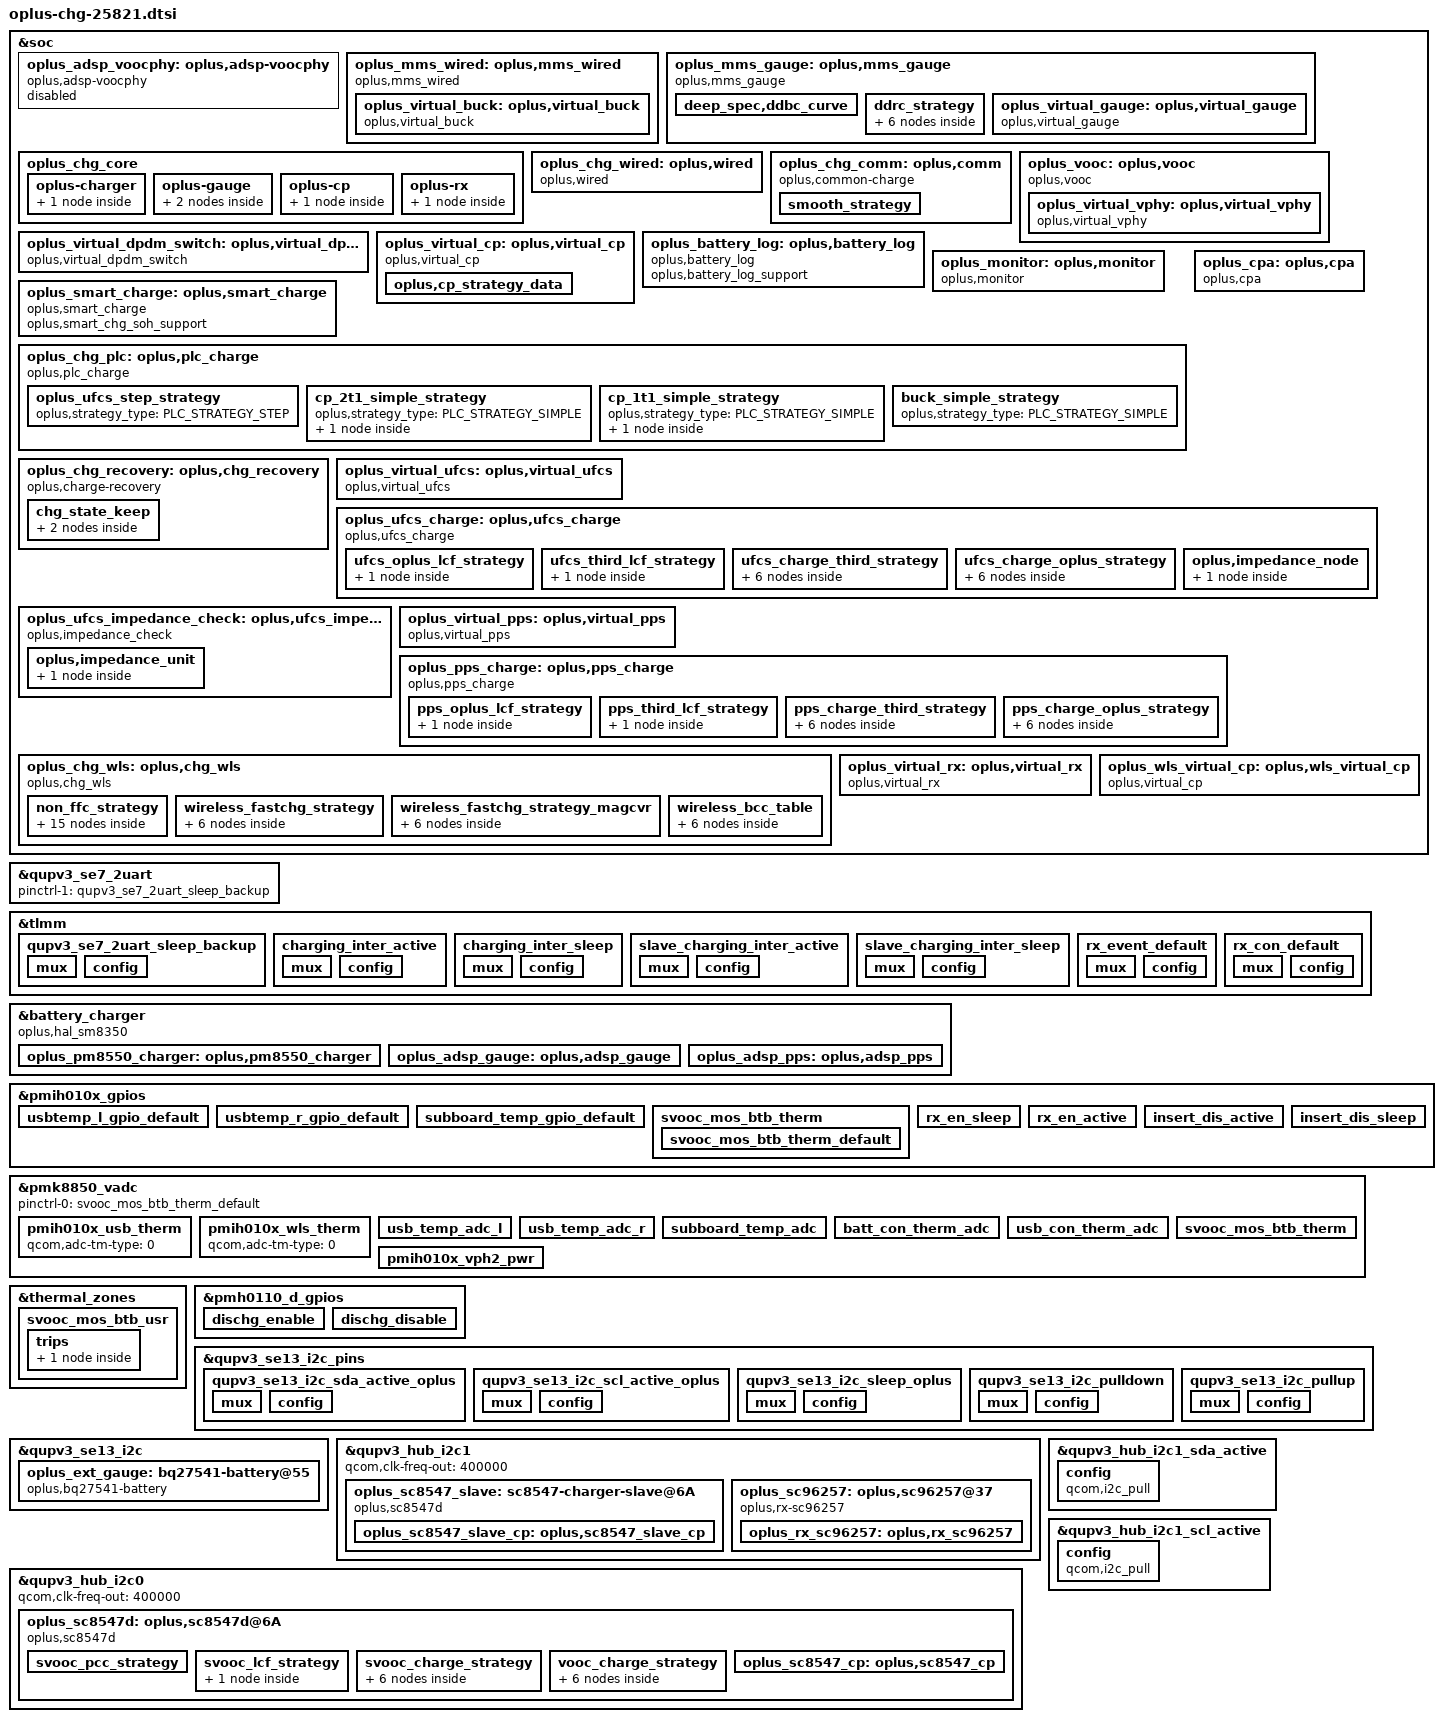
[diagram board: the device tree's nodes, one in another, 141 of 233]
#include "oplus-chg-8850.h.dtsi"
#include "oplus-chg-25821-fw.dtsi"

&soc {
	oplus_adsp_voocphy: oplus,adsp-voocphy {
		status = "disabled";
		compatible = "oplus,adsp-voocphy";
	};

	oplus_mms_wired: oplus,mms_wired {
		compatible = "oplus,mms_wired";
		oplus,buck_ic = <&oplus_virtual_buck>;
		oplus,voocphy_ic = <&oplus_virtual_vphy>;
		oplus,adc_info_name = "855";
		high-temp-scheme;

		oplus,support_usbtemp_protect_v2;
		oplus_spec,usbtemp_batt_temp_low = <50>;
		oplus_spec,usbtemp_batt_temp_high = <50>;
		oplus_spec,usbtemp_batt_temp_over_hot = <60>;
		oplus_spec,usbtemp_ntc_temp_low = <57>;
		oplus_spec,usbtemp_ntc_temp_high = <69>;
		oplus_spec,usbtemp_temp_gap_low_with_batt_temp = <7>;
		oplus_spec,usbtemp_temp_gap_with_batt_temp_in_over_hot = <15>;
		oplus_spec,usbtemp_temp_gap_high_with_batt_temp = <12>;
		oplus_spec,usbtemp_temp_gap_low_without_batt_temp = <12>;
		oplus_spec,usbtemp_temp_gap_high_without_batt_temp = <24>;
		oplus_spec,usbtemp_rise_fast_temp_low = <3>;
		oplus_spec,usbtemp_rise_fast_temp_high = <3>;
		oplus_spec,usbtemp_rise_fast_temp_count_low = <30>;
		oplus_spec,usbtemp_rise_fast_temp_count_high = <20>;
		oplus_spec,usbtemp_cool_down_ntc_low = <54>;
		oplus_spec,usbtemp_cool_down_ntc_high = <65>;
		oplus_spec,usbtemp_cool_down_gap_low = <12>;
		oplus_spec,usbtemp_cool_down_gap_high = <20>;
		oplus_spec,usbtemp_cool_down_recover_ntc_low = <48>;
		oplus_spec,usbtemp_cool_down_recover_ntc_high = <60>;
		oplus_spec,usbtemp_cool_down_recover_gap_low = <6>;
		oplus_spec,usbtemp_cool_down_recover_gap_high = <15>;
		oplus_spec,usbtemp_otg_cc_boot_current_limit = <2000>;

		oplus_virtual_buck: oplus,virtual_buck {
			compatible = "oplus,virtual_buck";
			oplus,buck_ic = <&oplus_pm8550_charger>;
			oplus,buck_ic_index = <0>;
			oplus,buck_ic_connect = <OPLUS_CHG_IC_CONNECT_PARALLEL>;
			oplus,main_charger = <0>;
			oplus,buck_ic_current_ratio = <100>;
			oplus,buck_ic_func_group = <&plat_pm8550_groups>;

			oplus,ic_type = <OPLUS_CHG_IC_VIRTUAL_BUCK>;
			oplus,ic_index = <0>;

			oplus,dischg-gpio = <&pmh0110_d_gpios 5 0x00>;
			oplus,usbtemp_conversion_ratio = <10>;

			pinctrl-names = "usbtemp_l_gpio_default", "usbtemp_r_gpio_default",
						"dischg_enable", "dischg_disable";
			pinctrl-0 = <&usbtemp_l_gpio_default>;
			pinctrl-1 = <&usbtemp_r_gpio_default>;
			pinctrl-2 = <&dischg_enable>;
			pinctrl-3 = <&dischg_disable>;

			io-channels = <&pmk8850_vadc PMIH010X_ADC5_GEN4_AMUX1_GPIO6_100K_PU(1, PMIH010X_SID)>,
					      <&pmk8850_vadc PMIH010X_ADC5_GEN4_AMUX5_GPIO18_100K_PU(1, PMIH010X_SID)>;
			io-channel-names = "usb_temp_adc_l", "usb_temp_adc_r";

			oplus,uart_tx-gpio = <&tlmm 62 0x00>;
			oplus,uart_rx-gpio = <&tlmm 63 0x00>;
		};
	};

	oplus_mms_gauge: oplus,mms_gauge {
		compatible = "oplus,mms_gauge";
		oplus,gauge_ic = <&oplus_virtual_gauge>;
		oplus,topic-update-interval = <5000>;
		oplus,support_subboard_ntc;
		oplus,sub_btb_curr_limit = <3000>;
		oplus,fcl_support;
		oplus,fcl_index = <0>;
		oplus,vb_offset = <20>;

		deep_spec,support;
		deep_spec,uv_thr = <2750>;
		deep_spec,count_thr = <50>;
		deep_spec,vbat_soc = <80>;
		deep_spec,count_step = <0 10 0
					350 12 1
					450 15 2
					530 20 3>;

		deep_spec,term_coeff = <2900 600 2
					2910 600 2
					2950 650 3
					3000 650 4
					3010 650 4
					3050 750 6
					3100 800 8
					3110 800 8
					3150 900 10
					3160 900 10
					3200 1000 12
					3210 1000 12
					3260 1050 12>;
		deep_spec,ddrc_strategy_name = "ddrc_curve_v2";
		deep_spec,volt_step = <20>;
		deep_spec,ddbc_curve {
			oplus,temp_type = <OPLUS_STRATEGY_USE_BATT_TEMP>;
			oplus,temp_range = <(-100) 0 200>;
			deep_spec,ddbc_temp_cold = <500 3250 5
						   10000 3200 2>;
			deep_spec,ddbc_temp_cool = <500 3250 5
						   10000 3200 2>;
			deep_spec,ddbc_temp_normal = <500 3250 5
						   10000 3200 2>;
			deep_spec,ddbc_temp_warm = <500 3250 5
						   10000 3200 2>;
		};

		ddrc_strategy {
			oplus,temp_type = <OPLUS_STRATEGY_USE_BATT_TEMP>;
			oplus,ratio_range = <20 30 50 70 90>;
			oplus,temp_range = <(-100) 0 100 200 350>;
			strategy_ratio_range_min {
				strategy_temp_0 =	<0 2753 3000 0
							300 2910 3100 1
							700 3010 3150 2
							1100 3061 3160 3
							1500 3111 3210 4
							1900 3161 3260 5>;
				strategy_temp_1 =	<0 2752 3100 0
							400 2910 3100 1
							900 3010 3150 2
							1400 3061 3160 3
							1900 3111 3210 4
							2400 3161 3260 5>;
				strategy_temp_2 =	<0 2752 3100 0
							400 2910 3100 1
							900 3010 3150 2
							1400 3061 3160 3
							1900 3111 3210 4
							2400 3161 3260 5>;
				strategy_temp_3 =	<0 2751 2950 0
							400 2911 3000 1
							900 3000 3010 2
							1400 3060 3110 3
							1900 3110 3160 4
							2400 3160 3210 5>;
				strategy_temp_4 =	<0 2750 2900 0
							400 2900 2910 1
							900 3000 3010 2
							1400 3050 3050 3
							1900 3100 3100 4
							2400 3150 3150 5>;
				strategy_temp_5 =	<0 2750 2900 0
							400 2900 2910 1
							900 3000 3010 2
							1400 3050 3050 3
							1900 3100 3100 4
							2400 3150 3150 5>;
			};
			strategy_ratio_range_low {
				strategy_temp_0 =	<0 2753 3000 0
							250 2910 3100 1
							550 3010 3150 2
							850 3110 3160 3
							1150 3160 3210 4
							1450 3210 3260 5>;
				strategy_temp_1 =	<0 2752 3100 0
							300 2910 3100 1
							700 3010 3150 2
							1100 3061 3160 3
							1500 3111 3210 4
							1900 3161 3260 5>;
				strategy_temp_2 =	<0 2752 3100 0
							300 2910 3100 1
							700 3010 3150 2
							1100 3061 3160 3
							1500 3111 3210 4
							1900 3161 3260 5>;
				strategy_temp_3 =	<0 2751 2950 0
							300 2911 3000 1
							700 3000 3010 2
							1100 3060 3110 3
							1500 3110 3160 4
							1900 3160 3210 5>;
				strategy_temp_4 =	<0 2750 2900 0
							300 2900 2910 1
							700 3000 3010 2
							1100 3050 3050 3
							1500 3100 3100 4
							1900 3150 3150 5>;
				strategy_temp_5 =	<0 2750 2900 0
							300 2900 2910 1
							700 3000 3010 2
							1100 3050 3050 3
							1500 3100 3100 4
							1900 3150 3150 5>;
			};
			strategy_ratio_range_mid_low {
				strategy_temp_0 =	<0 2753 3000 0
							100 2910 3100 1
							250 3010 3150 2
							400 3110 3160 3
							550 3160 3210 4
							700 3210 3260 5>;
				strategy_temp_1 =	<0 2752 3100 0
							100 2910 3100 1
							300 3010 3150 2
							600 3061 3160 3
							900 3111 3210 4
							1200 3161 3260 5>;
				strategy_temp_2 =	<0 2752 3100 0
							100 2910 3100 1
							300 3010 3150 2
							600 3061 3160 3
							900 3111 3210 4
							1200 3161 3260 5>;
				strategy_temp_3 =	<0 2751 2950 0
							100 2911 3000 1
							300 3000 3010 2
							600 3060 3110 3
							900 3110 3160 4
							1200 3160 3210 5>;
				strategy_temp_4 =	<0 2750 2900 0
							100 2900 2910 1
							300 3000 3010 2
							600 3050 3050 3
							900 3100 3100 4
							1200 3150 3150 5>;
				strategy_temp_5 =	<0 2750 2900 0
							100 2900 2910 1
							300 3000 3010 2
							600 3050 3050 3
							900 3100 3100 4
							1200 3150 3150 5>;
			};
			strategy_ratio_range_mid {
				strategy_temp_0 =	<0 2753 3000 0
							50 2910 3100 1
							150 3010 3150 2
							300 3110 3160 3
							450 3160 3210 4
							600 3210 3260 5>;
				strategy_temp_1 =	<0 2752 3100 0
							50 2910 3100 1
							150 3010 3150 2
							350 3061 3160 3
							550 3111 3210 4
							750 3161 3260 5>;
				strategy_temp_2 =	<0 2752 3100 0
							50 2910 3100 1
							150 3010 3150 2
							350 3061 3160 3
							550 3111 3210 4
							750 3161 3260 5>;
				strategy_temp_3 =	<0 2751 2950 0
							50 2911 3000 1
							150 3000 3010 2
							350 3060 3110 3
							550 3110 3160 4
							750 3160 3210 5>;
				strategy_temp_4 =	<0 2750 2900 0
							50 2900 2910 1
							150 3000 3010 2
							350 3050 3050 3
							550 3100 3100 4
							750 3150 3150 5>;
				strategy_temp_5 =	<0 2750 2900 0
							50 2900 2910 1
							150 3000 3010 2
							350 3050 3050 3
							550 3100 3100 4
							750 3150 3150 5>;
			};
			strategy_ratio_range_mid_high {
				strategy_temp_0 =	<0 2753 3000 0
							50 2910 3100 1
							150 3010 3150 2
							250 3110 3160 3
							350 3160 3210 4
							450 3210 3260 5>;
				strategy_temp_1 =	<0 2752 3100 0
							50 2910 3100 1
							150 3010 3150 2
							250 3061 3160 3
							350 3111 3210 4
							450 3161 3260 5>;
				strategy_temp_2 =	<0 2752 3100 0
							50 2910 3100 1
							150 3010 3150 2
							250 3061 3160 3
							350 3111 3210 4
							450 3161 3260 5>;
				strategy_temp_3 =	<0 2751 2950 0
							50 2911 3000 1
							150 3000 3010 2
							250 3060 3110 3
							350 3110 3160 4
							450 3160 3210 5>;
				strategy_temp_4 =	<0 2750 2900 0
							50 2900 2910 1
							150 3000 3010 2
							250 3100 3100 3
							350 3150 3150 4
							450 3200 3200 5>;
				strategy_temp_5 =	<0 2750 2900 0
							50 2900 2910 1
							150 3000 3010 2
							250 3100 3100 3
							350 3150 3150 4
							450 3200 3200 5>;
			};
			strategy_ratio_range_high {
				strategy_temp_0 =	<0 2753 3000 0
							50 2910 3100 1
							150 3010 3150 2
							250 3110 3160 3
							350 3160 3210 4
							450 3210 3260 5>;
				strategy_temp_1 =	<0 2752 3100 0
							50 2910 3100 1
							150 3010 3150 2
							250 3061 3160 3
							350 3111 3210 4
							450 3161 3260 5>;
				strategy_temp_2 =	<0 2752 3100 0
							50 2910 3100 1
							150 3010 3150 2
							250 3061 3160 3
							350 3111 3210 4
							450 3161 3260 5>;
				strategy_temp_3 =	<0 2751 2950 0
							50 2911 3000 1
							150 3000 3010 2
							250 3060 3110 3
							350 3110 3160 4
							450 3160 3210 5>;
				strategy_temp_4 =	<0 2750 2900 0
							50 2900 2910 1
							150 3000 3010 2
							250 3100 3100 3
							350 3150 3150 4
							450 3200 3200 5>;
				strategy_temp_5 =	<0 2750 2900 0
							50 2900 2910 1
							150 3000 3010 2
							250 3100 3100 3
							350 3150 3150 4
							450 3200 3200 5>;
			};
		};
		oplus_virtual_gauge: oplus,virtual_gauge {
			compatible = "oplus,virtual_gauge";
			oplus,gauge_ic = <&oplus_ext_gauge &oplus_adsp_gauge>;
			oplus,gauge_ic_index = <0 1>;
			oplus,gauge_ic_func_group = <&bq27541_groups &oplus_adsp_gauge_groups>;
			oplus,batt_capacity_mah = <7500>;
			oplus,ic_type = <OPLUS_CHG_IC_VIRTUAL_GAUGE>;
			oplus,ic_index = <0>;
		};
	};
};

&soc {
	oplus_chg_core {
		oplus,chg_framework_v2;
		oplus,smart_charging_screenoff;
		oplus,battery_type_by_smem;
		oplus,chg_spec_version = <OPLUS_CHG_SPEC_VER_V3P7>;
		oplus,common-charge-icl-support;

		oplus-charger {
			plat_pm8550_groups: oplus,plat_pm8550-groups {
				functions = <
					OPLUS_IC_FUNC_INIT
					OPLUS_IC_FUNC_EXIT
					OPLUS_IC_FUNC_REG_DUMP
					OPLUS_IC_FUNC_SMT_TEST
					OPLUS_IC_FUNC_BUCK_INPUT_PRESENT
					OPLUS_IC_FUNC_BUCK_INPUT_SUSPEND
					OPLUS_IC_FUNC_BUCK_INPUT_IS_SUSPEND
					OPLUS_IC_FUNC_BUCK_OUTPUT_SUSPEND
					OPLUS_IC_FUNC_BUCK_OUTPUT_IS_SUSPEND
					OPLUS_IC_FUNC_BUCK_GET_CC_ORIENTATION
					OPLUS_IC_FUNC_BUCK_GET_CHARGER_TYPE
					OPLUS_IC_FUNC_BUCK_RERUN_BC12
					OPLUS_IC_FUNC_BUCK_QC_DETECT_ENABLE
					OPLUS_IC_FUNC_BUCK_SHIPMODE_ENABLE
					OPLUS_IC_FUNC_BUCK_SET_QC_CONFIG
					OPLUS_IC_FUNC_BUCK_SET_PD_CONFIG
					OPLUS_IC_FUNC_GET_SHUTDOWN_SOC
					OPLUS_IC_FUNC_BACKUP_SOC
					OPLUS_IC_FUNC_GET_TYPEC_MODE
					OPLUS_IC_FUNC_BUCK_SET_ICL
					OPLUS_IC_FUNC_BUCK_GET_ICL
					OPLUS_IC_FUNC_BUCK_SET_FCC
					OPLUS_IC_FUNC_BUCK_SET_FV
					OPLUS_IC_FUNC_BUCK_SET_ITERM
					OPLUS_IC_FUNC_BUCK_SET_RECHG_VOL
					OPLUS_IC_FUNC_BUCK_GET_INPUT_CURR
					OPLUS_IC_FUNC_BUCK_GET_INPUT_VOL
					OPLUS_IC_FUNC_BUCK_AICL_RERUN
					OPLUS_IC_FUNC_BUCK_ITEM_CHECK
					OPLUS_IC_FUNC_GET_CHARGER_CYCLE
					OPLUS_IC_FUNC_OTG_BOOST_ENABLE
					OPLUS_IC_FUNC_SET_OTG_BOOST_CURR_LIMIT
					OPLUS_IC_FUNC_BUCK_GET_VBUS_COLLAPSE_STATUS
					OPLUS_IC_FUNC_GET_OTG_ENABLE
					OPLUS_IC_FUNC_SET_OTG_SWITCH_STATUS
					OPLUS_IC_FUNC_GET_OTG_SWITCH_STATUS
					OPLUS_IC_FUNC_GET_OTG_ONLINE_STATUS
					OPLUS_IC_FUNC_BUCK_GET_HW_DETECT
					OPLUS_IC_FUNC_VOOCPHY_SET_MATCH_TEMP
					OPLUS_IC_FUNC_IS_OPLUS_SVID
					OPLUS_IC_FUNC_BUCK_SET_VINDPM
					OPLUS_IC_FUNC_WLS_BOOST_ENABLE
					OPLUS_IC_FUNC_SET_WLS_BOOST_VOL
					OPLUS_IC_FUNC_SET_WLS_BOOST_CURR_LIMIT
					OPLUS_IC_FUNC_BUCK_WLS_INPUT_SUSPEND
					OPLUS_IC_FUNC_BUCK_SET_WLS_ICL
					OPLUS_IC_FUNC_BUCK_GET_WLS_ICL
					OPLUS_IC_FUNC_BUCK_GET_WLS_INPUT_CURR
					OPLUS_IC_FUNC_BUCK_GET_WLS_INPUT_VOL
					OPLUS_IC_FUNC_BUCK_WLS_AICL_ENABLE
					OPLUS_IC_FUNC_BUCK_WLS_AICL_RERUN
					OPLUS_IC_FUNC_BUCK_DIS_INSERT_DETECT
					OPLUS_IC_FUNC_GET_TYPEC_ROLE
					OPLUS_IC_FUNC_SET_TYPEC_MODE
					OPLUS_IC_FUNC_BUCK_GET_USB_BTB_TEMP
					OPLUS_IC_FUNC_BUCK_GET_BATT_BTB_TEMP
					OPLUS_IC_FUNC_BUCK_GET_USB_AICL_ENHANCE
					OPLUS_IC_FUNC_BUCK_SET_AICL_POINT
					OPLUS_IC_FUNC_BUCK_SET_OVP_FORCED
					OPLUS_IC_FUNC_BUCK_SET_DPDM_OVP_DISABLE
				>;
				virqs = <
					OPLUS_IC_VIRQ_ERR
					OPLUS_IC_VIRQ_CC_DETECT
					OPLUS_IC_VIRQ_PLUGIN
					OPLUS_IC_VIRQ_CC_CHANGED
					OPLUS_IC_VIRQ_SUSPEND_CHECK
					OPLUS_IC_VIRQ_CHG_TYPE_CHANGE
					OPLUS_IC_VIRQ_OTG_ENABLE
					OPLUS_IC_VIRQ_SVID
					OPLUS_IC_VIRQ_TYPEC_STATE
				>;
			};
		};

		oplus-gauge {
			bq27541_groups: oplus,bq27541_groups {
				functions = <
					OPLUS_IC_FUNC_INIT
					OPLUS_IC_FUNC_EXIT
					OPLUS_IC_FUNC_REG_DUMP
					OPLUS_IC_FUNC_SMT_TEST
					OPLUS_IC_FUNC_GAUGE_GET_BATT_VOL
					OPLUS_IC_FUNC_GAUGE_GET_BATT_MAX
					OPLUS_IC_FUNC_GAUGE_GET_BATT_MIN
					OPLUS_IC_FUNC_GAUGE_GET_BATT_CURR
					OPLUS_IC_FUNC_GAUGE_GET_BATT_TEMP
					OPLUS_IC_FUNC_GAUGE_GET_BATT_SOC
					OPLUS_IC_FUNC_GAUGE_GET_BATT_FCC
					OPLUS_IC_FUNC_GAUGE_GET_BATT_CC
					OPLUS_IC_FUNC_GAUGE_GET_BATT_RM
					OPLUS_IC_FUNC_GAUGE_GET_BATT_SOH
					OPLUS_IC_FUNC_GAUGE_GET_BATT_AUTH
					OPLUS_IC_FUNC_GAUGE_GET_BATT_HMAC
					OPLUS_IC_FUNC_GAUGE_UPDATE_DOD0
					OPLUS_IC_FUNC_GAUGE_UPDATE_SOC_SMOOTH
					OPLUS_IC_FUNC_GAUGE_GET_CB_STATUS
					OPLUS_IC_FUNC_GAUGE_GET_BATT_NUM
					OPLUS_IC_FUNC_GAUGE_GET_DEVICE_TYPE
					OPLUS_IC_FUNC_GAUGE_GET_DEVICE_TYPE_FOR_VOOC
					OPLUS_IC_FUNC_GAUGE_GET_BATT_FCC
					OPLUS_IC_FUNC_GAUGE_GET_BATT_FC
					OPLUS_IC_FUNC_GAUGE_GET_BATT_QM
					OPLUS_IC_FUNC_GAUGE_GET_BATT_PD
					OPLUS_IC_FUNC_GAUGE_GET_BATT_RCU
					OPLUS_IC_FUNC_GAUGE_GET_BATT_RCF
					OPLUS_IC_FUNC_GAUGE_GET_BATT_FCU
					OPLUS_IC_FUNC_GAUGE_GET_BATT_FCF
					OPLUS_IC_FUNC_GAUGE_GET_BATT_SOU
					OPLUS_IC_FUNC_GAUGE_GET_BATT_DO0
					OPLUS_IC_FUNC_GAUGE_GET_BATT_DOE
					OPLUS_IC_FUNC_GAUGE_GET_BATT_TRM
					OPLUS_IC_FUNC_GAUGE_GET_BATT_PC
					OPLUS_IC_FUNC_GAUGE_GET_BATT_QS
					OPLUS_IC_FUNC_GAUGE_IS_SUSPEND
					OPLUS_IC_FUNC_GAUGE_GET_BCC_PARMS
					OPLUS_IC_FUNC_GAUGE_FASTCHG_UPDATE_BCC_PARMS
					OPLUS_IC_FUNC_GAUGE_GET_PREV_BCC_PARMS
					OPLUS_IC_FUNC_GAUGE_SET_BCC_PARMS
					OPLUS_IC_FUNC_GAUGE_GET_DEVICE_TYPE_FOR_BCC
					OPLUS_IC_FUNC_GAUGE_GET_DOD0
					OPLUS_IC_FUNC_GAUGE_GET_DOD0_PASSED_Q
					OPLUS_IC_FUNC_GAUGE_GET_QMAX
					OPLUS_IC_FUNC_GAUGE_GET_QMAX_PASSED_Q
					OPLUS_IC_FUNC_GAUGE_GET_DEEP_DISCHG_COUNT
					OPLUS_IC_FUNC_GAUGE_SET_DEEP_DISCHG_COUNT
					OPLUS_IC_FUNC_GAUGE_SET_DEEP_TERM_VOLT
					OPLUS_IC_FUNC_GAUGE_GET_REG_INFO
					OPLUS_IC_FUNC_GAUGE_GET_CALIB_TIME
					OPLUS_IC_FUNC_GAUGE_GET_BATT_SN
					OPLUS_IC_FUNC_GAUGE_GET_DEEP_TERM_VOLT
					OPLUS_IC_FUNC_GAUGE_SET_SILI_SPARE_POWER
					OPLUS_IC_FUNC_GAUGE_GET_SILI_SIMULATE_TERM_VOLT
					OPLUS_IC_FUNC_GAUGE_GET_SILI_IC_ALG_TERM_VOLT
					OPLUS_IC_FUNC_GAUGE_SET_SILI_IC_ALG_CFG
					OPLUS_IC_FUNC_GAUGE_GET_SILI_IC_ALG_DSG_ENABLE
					OPLUS_IC_FUNC_GAUGE_SET_SILI_IC_ALG_TERM_VOLT
					OPLUS_IC_FUNC_GAUGE_GET_SILI_ALG_APPLICATION_INFO
					OPLUS_IC_FUNC_GAUGE_GET_SILI_LIFETIME_STATUS
					OPLUS_IC_FUNC_GAUGE_GET_SILI_LIFETIME_INFO
					OPLUS_IC_FUNC_GAUGE_GET_MANU_DATE
					OPLUS_IC_FUNC_GAUGE_GET_FIRST_USAGE_DATE
					OPLUS_IC_FUNC_GAUGE_SET_FIRST_USAGE_DATE
					OPLUS_IC_FUNC_GAUGE_GET_UI_CC
					OPLUS_IC_FUNC_GAUGE_SET_UI_CC
					OPLUS_IC_FUNC_GAUGE_GET_UI_SOH
					OPLUS_IC_FUNC_GAUGE_SET_UI_SOH
					OPLUS_IC_FUNC_GAUGE_GET_USED_FLAG
					OPLUS_IC_FUNC_GAUGE_SET_USED_FLAG
					OPLUS_IC_FUNC_GAUGE_SET_CALIB_TIME
					OPLUS_IC_FUNC_GAUGE_SET_LAST_CC
					OPLUS_IC_FUNC_GAUGE_GET_LAST_CC
					OPLUS_IC_FUNC_GAUGE_GET_CHEM_ID
					OPLUS_IC_FUNC_GAUGE_GET_DEC_FG_TYPE
					OPLUS_IC_FUNC_GAUGE_GET_DEC_CV_SOH
					OPLUS_IC_FUNC_GAUGE_SET_VCT
					OPLUS_IC_FUNC_GAUGE_GET_VCT
					OPLUS_IC_FUNC_GAUGE_GET_GAUGE_CAR_C
					OPLUS_IC_FUNC_GAUGE_GET_BATT_SOC_CENTI
					OPLUS_IC_FUNC_GAUGE_SET_FAST_SAMPLING
				>;
				virqs = <
					OPLUS_IC_VIRQ_ERR
					OPLUS_IC_VIRQ_OFFLINE
					OPLUS_IC_VIRQ_RESUME
				>;
			};

			oplus_adsp_gauge_groups: oplus,oplus_adsp_gauge_groups {
				functions = <
					OPLUS_IC_FUNC_INIT
					OPLUS_IC_FUNC_EXIT
					OPLUS_IC_FUNC_REG_DUMP
					OPLUS_IC_FUNC_SMT_TEST
					OPLUS_IC_FUNC_GAUGE_GET_SUBBOARD_TEMP
					OPLUS_IC_FUNC_GAUGE_GET_FCL_VOLT
				>;
				virqs = <
					OPLUS_IC_VIRQ_ERR
				>;
			};
		};

		oplus-cp {
			sc8547_cp_groups: oplus,cp_groups {
				functions = <
					OPLUS_IC_FUNC_INIT
					OPLUS_IC_FUNC_EXIT
					OPLUS_IC_FUNC_REG_DUMP
					OPLUS_IC_FUNC_SMT_TEST
					OPLUS_IC_FUNC_CP_ENABLE
					OPLUS_IC_FUNC_CP_HW_INTI
					OPLUS_IC_FUNC_CP_SET_WORK_MODE
					OPLUS_IC_FUNC_CP_GET_WORK_MODE
					OPLUS_IC_FUNC_CP_CHECK_WORK_MODE_SUPPORT
					OPLUS_IC_FUNC_CP_SET_IIN
					OPLUS_IC_FUNC_CP_GET_VIN
					OPLUS_IC_FUNC_CP_GET_IIN
					OPLUS_IC_FUNC_CP_GET_VOUT
					OPLUS_IC_FUNC_CP_GET_IOUT
					OPLUS_IC_FUNC_CP_SET_WORK_START
					OPLUS_IC_FUNC_CP_GET_WORK_STATUS
					OPLUS_IC_FUNC_CP_SET_ADC_ENABLE
					OPLUS_IC_FUNC_CP_WATCHDOG_ENABLE
					OPLUS_IC_FUNC_CP_SET_UCP_DISABLE
					OPLUS_IC_FUNC_CP_GET_IIN_MAX
					OPLUS_IC_FUNC_CP_WATCHDOG_RESET
				>;
				virqs = <
					OPLUS_IC_VIRQ_ERR
					OPLUS_IC_VIRQ_ONLINE
					OPLUS_IC_VIRQ_OFFLINE
				>;
			};
		};

		oplus-rx {
			sc96257_rx_groups: oplus,rx_groups {
				functions = <
					OPLUS_IC_FUNC_INIT
					OPLUS_IC_FUNC_EXIT
					OPLUS_IC_FUNC_REG_DUMP
					OPLUS_IC_FUNC_SMT_TEST
					OPLUS_IC_FUNC_RX_SET_ENABLE
					OPLUS_IC_FUNC_RX_IS_ENABLE
					OPLUS_IC_FUNC_RX_IS_CONNECTED
					OPLUS_IC_FUNC_RX_GET_VOUT
					OPLUS_IC_FUNC_RX_SET_VOUT
					OPLUS_IC_FUNC_RX_GET_VRECT
					OPLUS_IC_FUNC_RX_GET_IOUT
					OPLUS_IC_FUNC_RX_GET_TRX_VOL
					OPLUS_IC_FUNC_RX_GET_TRX_CURR
					OPLUS_IC_FUNC_RX_GET_CEP_COUNT
					OPLUS_IC_FUNC_RX_GET_CEP_VAL
					OPLUS_IC_FUNC_RX_GET_WORK_FREQ
					OPLUS_IC_FUNC_RX_GET_RX_MODE
					OPLUS_IC_FUNC_RX_SET_RX_MODE
					OPLUS_IC_FUNC_RX_SET_DCDC_ENABLE
					OPLUS_IC_FUNC_RX_SET_TRX_ENABLE
					OPLUS_IC_FUNC_RX_SET_TRX_START
					OPLUS_IC_FUNC_RX_GET_TRX_STATUS
					OPLUS_IC_FUNC_RX_GET_TRX_ERR
					OPLUS_IC_FUNC_RX_GET_HEADROOM
					OPLUS_IC_FUNC_RX_SET_HEADROOM
					OPLUS_IC_FUNC_RX_SEND_MATCH_Q
					OPLUS_IC_FUNC_RX_SET_FOD_PARM
					OPLUS_IC_FUNC_RX_SEND_MSG
					OPLUS_IC_FUNC_RX_REG_MSG_CALLBACK
					OPLUS_IC_FUNC_RX_GET_RX_VERSION
					OPLUS_IC_FUNC_RX_GET_TRX_VERSION
					OPLUS_IC_FUNC_RX_UPGRADE_FW_BY_BUF
					OPLUS_IC_FUNC_RX_UPGRADE_FW_BY_IMG
					OPLUS_IC_FUNC_RX_CHECK_CONNECT
					OPLUS_IC_FUNC_RX_GET_EVENT_CODE
					OPLUS_IC_FUNC_RX_GET_BRIDGE_MODE
					OPLUS_IC_FUNC_RX_DIS_INSERT
					OPLUS_IC_FUNC_RX_STANDBY_CONFIG
					OPLUS_IC_FUNC_RX_SET_COMU
					OPLUS_IC_FUNC_RX_GET_TX_ID
					OPLUS_IC_FUNC_RX_SET_SILENT
				>;
				virqs = <
					OPLUS_IC_VIRQ_ERR
					OPLUS_IC_VIRQ_PRESENT
					OPLUS_IC_VIRQ_ONLINE
					OPLUS_IC_VIRQ_OFFLINE
					OPLUS_IC_VIRQ_EVENT_CHANGED
				>;
			};
		};
	};
};

&soc {
	oplus_chg_wired: oplus,wired {
		compatible = "oplus,wired";

		oplus,vooc-support;
		oplus,qc-curr-check-support;
		oplus_spec,vbatt_pdqc_to_5v_thr = <4500>;
		oplus_spec,vbatt_pdqc_to_9v_thr = <4500>;
		oplus_spec,pd-iclmax-ma = <2000>;
		oplus_spec,qc-iclmax-ma = <2000>;
		oplus_spec,non-standard-ibatmax-ma = <500>;
		oplus_spec,input-power-mw = <
			2500		/* OPLUS_WIRED_CHG_MODE_UNKNOWN */
			2500		/* OPLUS_WIRED_CHG_MODE_SDP */
			7500		/* OPLUS_WIRED_CHG_MODE_CDP */
			10000		/* OPLUS_WIRED_CHG_MODE_DCP */
			10000		/* OPLUS_WIRED_CHG_MODE_VOOC */
			18000		/* OPLUS_WIRED_CHG_MODE_QC */
			18000		/* OPLUS_WIRED_CHG_MODE_PD */
		>;
		oplus_spec,led_on-fccmax-ma = <0 676 2029 3382 4400 4400 4400 1000 0>;
		oplus_spec,fccmax-ma-lv = <
			0 750  2200 2200 2200 2200 2200 2200 0	/* OPLUS_WIRED_CHG_MODE_UNKNOWN */
			0 600  600  600  600  600  600  600  0	/* OPLUS_WIRED_CHG_MODE_SDP */
			0 676  1600 1600 1600 1600 1600 1600 0	/* OPLUS_WIRED_CHG_MODE_CDP */
			0 676  2029 2200 2200 2200 2200 2200 0	/* OPLUS_WIRED_CHG_MODE_DCP */
			0 750  2200 2200 2200 2200 2200 2200 0	/* OPLUS_WIRED_CHG_MODE_VOOC */
			0 676  2029 3382 4400 4400 4400 4058 0	/* OPLUS_WIRED_CHG_MODE_QC */
			0 676  2029 3382 4400 4400 4400 4058 0	/* OPLUS_WIRED_CHG_MODE_PD */
		>;
		oplus_spec,fccmax-ma-hv = <
			0 395  750  1501 2200 2200 2200 2200 0	/* OPLUS_WIRED_CHG_MODE_UNKNOWN */
			0 356  600  600  600  600  600  600  0	/* OPLUS_WIRED_CHG_MODE_SDP */
			0 356  676  1352 1600 1600 1600 1600 0	/* OPLUS_WIRED_CHG_MODE_CDP */
			0 356  676  1352 2029 2200 2200 2200 0	/* OPLUS_WIRED_CHG_MODE_DCP */
			0 395  750  1501 2200 2200 2200 2200 0	/* OPLUS_WIRED_CHG_MODE_VOOC */
			0 356  676  1352 2029 3382 4400 4058 0	/* OPLUS_WIRED_CHG_MODE_QC */
			0 356  676  1352 2029 3382 4400 4058 0	/* OPLUS_WIRED_CHG_MODE_PD */
		>;

		oplus_spec,cool_down_sale_pdqc_vol_mv = <5000>;
		oplus_spec,cool_down_sale_pdqc_curr_ma = <1200>;
		oplus_spec,cool_down_pdqc_vol_mv = <5000 5000 5000 9000 9000>;
		oplus_spec,cool_down_pdqc_curr_ma = <1200 1500 2000 1500 2000>;
		oplus_spec,cool_down_vooc_curr_ma = <1200 1500 2000 2500 3000 3000>;
		oplus_spec,cool_down_normal_curr_ma = <1200 1500 2000>;

		oplus_spec,vbus_ov_thr_mv = <11000 11000>;
		oplus_spec,vbus_uv_thr_mv = <4300 4300>;

		/* first data is strategy used temp type */
		oplus,pd_strategy_name = "cgcl";
		oplus,pd_strategy_data = <OPLUS_STRATEGY_USE_SHELL_TEMP
					    0   420 2000 1 0
					    410 430 1500 2 0
					    420 440 1200 2 1>;
		oplus,qc_strategy_name = "cgcl";
		oplus,qc_strategy_data = <OPLUS_STRATEGY_USE_SHELL_TEMP
					    0   420 2000 1 0
					    410 430 1500 2 0
					    420 440 1200 2 1>;
	};

	oplus_chg_comm: oplus,comm {
		compatible = "oplus,common-charge";
		oplus_spec,dec_step = <20>;
		oplus_spec,dec-vol-cc-full-thr = <0 200 400 600 800 1000>;
		oplus_spec,dec-vol-fv-full-mv = <0 20 40 40 60 60>;
		oplus_spec,batt-them-thr = <(-100) 0 50 120 160 350 450 530>;
		oplus_spec,iterm-ma = <366>;
		oplus_spec,removed_bat_decidegc = <390>;
		oplus_spec,fv-mv = <4500 4500 4500 4500 4500 4500 4485 4130 4130>;
		oplus_spec,sw-fv-mv = <4450 4450 4450 4450 4450 4450 4435 4080 4080>;
		oplus_spec,hw-fv-inc-mv = <0 18 18 18 18 18 18 18 0>;
		oplus_spec,sw-over-fv-mv = <4508 4508 4508 4508 4508 4508 4493 4138 4138>;
		oplus_spec,sw-over-fv-dec-mv = <10>;
		oplus_spec,non-standard-sw-fv-mv = <3930>;
		oplus_spec,non-standard-fv-mv = <3980>;
		oplus_spec,non-standard-hw-fv-inc-mv = <18>;
		oplus_spec,non-standard-sw-over-fv-mv = <3990>;
		oplus_spec,non-standard-vbatdet-mv = <3680>;
		oplus_spec,wired-vbatdet-mv = <0 4200 4300 4400 4400 4400 4385 4030 0>;
		oplus_spec,wls-vbatdet-mv = <0 4200 4300 4400 4400 4400 4385 4030 0>;
		oplus_spec,fcc-gear-thr-mv = <3980>;
		oplus_spec,fcc-gear-shake-mv = <400 400 400 300 300 180 180 180 180>;
		oplus_spec,vbatt-ov-thr-mv = <4600>;

		oplus_spec,full_pre_ffc_judge;
		oplus_spec,full-pre-ffc-mv = <4495>;
		oplus_spec,ffc-temp-thr = <120 210 350 440>;
		oplus_spec,wired-ffc-step-max = <5>;
		oplus_spec,wired-ffc-fv-mv = <4630 4630 4630 4630 4630>;

		oplus_spec,wired-ffc-fv-cutoff-mv = <4545 4545 4530
						     4545 4540 4525
						     4545 4540 4525
						     4540 4540 4520
						     4535 4540 4520>;
		oplus_spec,wired-ffc-fcc-ma = <1500 1500 1500
					       1400 1400 1400
					       1300 1300 1300
					       1200 1200 1200
					       1100 1100 1100>;
		oplus_spec,wired-ffc-fcc-cutoff-ma = <1350 1350 1350
						      1250 1250 1250
						      1150 1150 1150
						      1050 1050 1050
						      950  950  950>;

		oplus_spec,wls-ffc-step-max = <2>;
		oplus_spec,wls-ffc-fv-mv = <4630 4630>;
		oplus_spec,wls-ffc-fv-cutoff-mv = <4545 4545 4530
						   4545 4545 4520>;
		oplus_spec,wls-ffc-icl-ma = <1150 1250 1150
					     950 1150 750>;
		oplus_spec,wls-ffc-fcc-ma = <1500 1600 1500
					     1300 1500 1000>;
		oplus_spec,wls-ffc-fcc-cutoff-ma = <1300 1400 1300
						    1200 1300 900>;
		oplus_spec,wls-ffc-fcc-sub-cutoff-ma = <1300 1400 1300
						    1200 1300 900>;

		oplus_spec,vbat_uv_thr_mv = <2750>;
		oplus_spec,vbat_charging_uv_thr_mv = <2650>;

		oplus_spec,tbatt_power_off_cali_temp = <0>;
		oplus_spec,poweroff_high_batt_temp = <720>;
		oplus_spec,poweroff_emergency_batt_temp = <770>;
		oplus,vooc_show_ui_soc_decimal;
		oplus,ui_soc_decimal_speedmin = <20>;

		oplus,gauge_stuck_jump_support;
		oplus,gauge_stuck_threshold = <15>;
		oplus,gauge_stuck_time = <50>;

		oplus_spec,sw_check_full_cnt = <12>;
		oplus,ui_soc_2_voltage_comp_mv = <30>;
		oplus,chg_shutdown_max_mv = <2750>;

		oplus_spec,drop_soc_2_temp_ladder = <(-50) 0 0 0 0 0 0 0 0 0>;
		oplus_spec,volt_diff_ladder_of_drop_soc_2 = <80 80 0 0 0 0 0 0 0 0>;
		oplus_spec,keep_soc_2_temp_ladder = <(-200) (-50) 0 0 0 0 0 0 0 0>;
		oplus_spec,volt_diff_ladder_of_keep_soc_2 = <10 20 30 0 0 0 0 0 0 0>;
		oplus_spec,back_rm_of_drop_soc_2 = <37>;
		oplus_spec,back_rm_of_drop_soc_1 = <0>;
		oplus_spec,load_current_of_drop_soc_2 = <1500>;
		oplus_spec,load_current_of_drop_soc_1 = <2000>;
		oplus_spec,current_limit_of_drop_soc_2 = <700>;
		oplus_spec,volt_of_fast_drop_soc_1 = <2750>;
		oplus_spec,support_uisoc_low_battery_control;
		oplus_spec,soc_down_ladder = <2 11 60 95 100 0 0 0 0 0>;
		oplus_spec,soc_down_delay_hz_ladder = <20 20 40 60 150 300 0 0 0 0>;
		oplus_spec,soc_down_chg_delay_hz_ladder = <90 40 40 60 150 300 0 0 0 0>;
		oplus_spec,soc_down_default_delay_hz = <40>;

		oplus_spec,batt_full_time = <60>;
		oplus_spec,batt_full_low_soc = <99>;
		oplus_spec,batt_full_low_soc_time = <600>;
		oplus_spec,smooth_strategy_name = "bs";
		oplus_spec,hw_iterm_support;
		smooth_strategy {
			oplus_spec,reserve_table_centipercent =
				/* start(%) end(%) dischg_reserve(0.01%) full_reserve(0.01%) chg_reserve(0.01%) chg_split(%) */
				<0   20  0   0   200 100>,
				<21  99  200 0   200 100>,
				<100 100 200 0   200 100>;
		};
	};

	oplus_vooc: oplus,vooc {
		compatible = "oplus,vooc";
		oplus,vooc_ic = <&oplus_virtual_vphy>;

		oplus_spec,vooc_soc_range = <55 75 85>;

		oplus,vooc_data_width = <7>;
		oplus,vooc_curr_max = <CP_CURR_LIMIT_7BIT_19_0A>;
		oplus,vooc_project = <VOOC_PROJECT_10V10A_TWO_BAT_SVOOC>;
		oplus,vooc_curr_table_type = <VOOC_CP_CURR_TABLE>;
		oplus,vooc_power_max_w = <100>;
		oplus,voocphy_support = <AP_DUAL_CP_VOOCPHY>;
		oplus,support_fake_vooc_check;
		oplus,smart_chg_bcc_support;
		oplus,subboard_ntc_abnormal_current = <4000>;
		oplus,cp_cooldown_limit_percent_75 = <CP_CURR_LIMIT_7BIT_6_0A>;
 		oplus,cp_cooldown_limit_percent_85 = <CP_CURR_LIMIT_7BIT_4_0A>;
		oplus,qc_detect_dpdm_ovp_disable;

		/* first data is strategy used temp type */
		oplus,general_strategy_name = "cgcl";
		oplus,general_strategy_data = <OPLUS_STRATEGY_USE_SHELL_TEMP
						0   385 CP_CURR_LIMIT_7BIT_19_0A 1 0
						375 405 CP_CURR_LIMIT_7BIT_10_0A 2 0
						395 420 CP_CURR_LIMIT_7BIT_8_0A  3 1
						410 430 CP_CURR_LIMIT_7BIT_7_0A  4 2
						420 440 CP_CURR_LIMIT_7BIT_4_0A  4 3>;

		oplus,bypass_strategy_name = "cgcl";
		oplus,bypass_strategy_data = <OPLUS_STRATEGY_USE_SHELL_TEMP
						0   395 CP_CURR_LIMIT_7BIT_6_0A  1 0
						385 405 CP_CURR_LIMIT_7BIT_4_0A  2 0
						395 415 CP_CURR_LIMIT_7BIT_3_0A  3 1
						405 440 CP_CURR_LIMIT_7BIT_2_0A  3 2>;

		oplus,plc_strategy-data = <&buck_simple_strategy &cp_2t1_simple_strategy &cp_1t1_simple_strategy>;
		oplus,plc_strategy-names = "default", "svooc", "vooc";

		oplus_virtual_vphy: oplus,virtual_vphy {
			compatible = "oplus,virtual_vphy";
			oplus,vphy_ic = <&oplus_sc8547d>;
			oplus,dpdm_switch_ic = <&oplus_virtual_dpdm_switch>;

			oplus,ic_type = <OPLUS_CHG_IC_VIRTUAL_VPHY>;
			oplus,ic_index = <0>;
		};
	};

	oplus_virtual_dpdm_switch: oplus,virtual_dpdm_switch {
		compatible = "oplus,virtual_dpdm_switch";
		oplus,ic_type = <OPLUS_CHG_IC_MISC>;
		oplus,ic_index = <0>;
		oplus,use_audio_switch;
	};

	oplus_virtual_cp: oplus,virtual_cp {
		compatible = "oplus,virtual_cp";

		oplus,ic_type = <OPLUS_CHG_IC_VIRTUAL_CP>;
		oplus,ic_index = <0>;

		oplus,cp_ic = <&oplus_sc8547_cp &oplus_sc8547_slave_cp>;
		oplus,input_curr_max_ma = <5000 5000>;

		oplus,cp_ic_connect = <OPLUS_CHG_IC_CONNECT_PARALLEL>;
		oplus,main_cp = <0>;

		oplus,reg_proc_node;

		oplus,cp_strategy = <CP_STRAT_OPEN_BY_CURR>;
		oplus,cp_strategy_data {
			oplus,cp_open_curr_thr_ma = <0 1900>;
			oplus,cp_close_curr_thr_ma = <0 1600>;
		};
	};
};

&soc {
	oplus_battery_log: oplus,battery_log {
		compatible = "oplus,battery_log";
		oplus,battery_log_support;
	};

	oplus_monitor: oplus,monitor {
		compatible = "oplus,monitor";
		oplus,topic-update-interval = <60000>;

		track,fast_chg_break_t_thd = <2500>;
		track,general_chg_break_t_thd = <300>;
		track,voocphy_type = <TRACK_AP_DUAL_CP_VOOCPHY>;
		track,wired_max_power = <100000>;
		track,wired_fast_chg_scheme = <TRACK_WIRED_SCHEME_SINGLE_60W_67W>;

		track,gauge_status_ctrl;
		track,nominal_qmax1 = <8262>;
		track,nominal_fcc1 = <7512>;
		track,external_gauge_num = <1>;

		track,gauge_max_cell_vol = <4600>;
		track,gauge_max_charge_curr = <13000>;
		track,gauge_max_dischg_curr = <6000>;
		track,gauge_min_cell_temp = <30>;
		track,gauge_max_cell_temp = <70>;
		track,gauge_lifetime_support;

		track,low_soc_monitor_ctrl;
		track,track_ver = <TRACK_VER_4_0>;
	};

	oplus_smart_charge: oplus,smart_charge {
		compatible = "oplus,smart_charge";
		oplus,smart_chg_soh_support;
	};

	oplus_chg_plc: oplus,plc_charge {
		compatible = "oplus,plc_charge";
		oplus,plc_soc = <90>;
		oplus,plc_support_timeout;
		oplus,plc_strategy-data = <&buck_simple_strategy>;
		oplus,plc_strategy-names = "default";

		oplus_ufcs_step_strategy: oplus_ufcs_step_strategy {
			oplus,strategy_type = <PLC_STRATEGY_STEP>;
		};

		cp_2t1_simple_strategy: cp_2t1_simple_strategy {
			oplus,strategy_type = <PLC_STRATEGY_SIMPLE>;
			oplus,strategy_data {
				strategy_curr_ma = <1000 1500>;
			};
		};

		cp_1t1_simple_strategy: cp_1t1_simple_strategy {
			oplus,strategy_type = <PLC_STRATEGY_SIMPLE>;
			oplus,strategy_data {
				strategy_curr_ma = <2000 3000>;
			};
		};

		buck_simple_strategy: buck_simple_strategy {
			oplus,strategy_type = <PLC_STRATEGY_SIMPLE>;
		};
	};
};

/*for ufcs config*/
&soc {
	oplus_chg_recovery: oplus,chg_recovery {
		compatible = "oplus,charge-recovery";

		chg_state_keep {
			wired_disconnect_detection {
				protocol_switch_table = <
					CHG_PROTOCOL_UFCS  44  3  3
					CHG_PROTOCOL_PPS    0  3  3
					CHG_PROTOCOL_VOOC   0  1  1
					CHG_PROTOCOL_PD     0  3  3
					CHG_PROTOCOL_QC     0  3  3
					CHG_PROTOCOL_BC12   0  3  3
				>;
			};
			vooc_disconnect_detection {};
		};
	};

	oplus_cpa: oplus,cpa {
		compatible = "oplus,cpa";
		/* format: <protocol_type power_w> */
		oplus,protocol_list = <CHG_PROTOCOL_UFCS  100
					   CHG_PROTOCOL_VOOC 100
					   CHG_PROTOCOL_PPS  55
					   CHG_PROTOCOL_PD   18
					   CHG_PROTOCOL_QC   18>;
		oplus,default_protocol_list = <CHG_PROTOCOL_UFCS
						   CHG_PROTOCOL_VOOC
						   CHG_PROTOCOL_PPS
						   CHG_PROTOCOL_PD>;
	};

	oplus_virtual_ufcs: oplus,virtual_ufcs {
		compatible = "oplus,virtual_ufcs";

		oplus,ic_type = <OPLUS_CHG_IC_VIRTUAL_UFCS>;
		oplus,ic_index = <0>;
	};

	oplus_ufcs_charge: oplus,ufcs_charge {
		compatible = "oplus,ufcs_charge";
		oplus,ufcs_ic = <&oplus_virtual_ufcs>;
		oplus,cp_ic = <&oplus_virtual_cp>;
		oplus,dpdm_switch_ic = <&oplus_virtual_dpdm_switch>;

		oplus,impedance_unit = <&oplus_ufcs_impedance_unit>;

		oplus,target_vbus_mv = <11000>;
		oplus,curr_max_ma = <9100>;
		oplus,curr_max_ma_percent = <3000 /* 75% ibus */
					     2000 /* 85% ibus */>;
		oplus,curr_table_type = <UFCS_CURR_CP_TABLE>;
		oplus,high_imp_compensation_setting_mv = <250>;
		oplus,upper_compensation_mv = <200>;
		oplus,subboard_ntc_abnormal_current = <4000>;
		oplus,lift_vbus_use_cpvout;
		oplus,ufcs_need_reset_adapter;

		oplus,support_pr;
		oplus,pr_r_input_mohm = <100>;
		oplus,pr_r_btb_mohm = <10>;

		oplus,ufcs_warm_allow_vol = <4000>;
		oplus,ufcs_warm_allow_soc = <55>;
		oplus,ufcs_strategy_normal_current = <9100>;
		oplus,ufcs_over_high_or_low_current = <9100>;
		oplus,ufcs_ibus_over_oplus = <9800>;
		oplus,ufcs_timeout_third = <18308>;
		oplus,ufcs_timeout_oplus = <18308>;
		oplus,ufcs_ibat_over_third = <9400>;
		oplus,ufcs_ibat_over_oplus = <19600>;
		oplus,ufcs_full_cool_sw_vbat = <4050>;
		oplus,ufcs_full_normal_sw_vbat = <4550>;
		oplus,ufcs_full_normal_hw_vbat = <4560>;
		oplus,ufcs_full_warm_vbat = <4130>;
		oplus,ufcs_full_cool_sw_vbat_third = <4050>;
		oplus,ufcs_full_normal_sw_vbat_third = <4550>;
		oplus,ufcs_full_normal_hw_vbat_third = <4560>;
		oplus,ufcs_strategy_batt_high_temp = <405 420 430 395 410 425>;
		oplus,ufcs_strategy_high_current = <5000 2500 2000 9100 5000 2500>;
		oplus,ufcs_little_cool_high_temp = <210>;
		oplus,curve_strategy_name = "pps_ufcs_curve_v2";
		oplus,ufcs_full_recheck_temp = <210>;
		oplus,ufcs_charge_strategy_temp = <50 50 120 160 350 440 510>;
		oplus_spec,ufcs_low_temp = <50>;
		oplus_spec,ufcs_high_temp = <500>;
		oplus_spec,ufcs_low_soc = <0>;
		oplus_spec,ufcs_high_soc = <95>;
		oplus_spec,ufcs_high_soc_third = <95>;

		oplus,temperature_strategy_name = "cgcl";
		oplus,temperature_strategy_data = <OPLUS_STRATEGY_USE_SHELL_TEMP
						0   385 9100 1 0
						375 405 5000 2 0
						395 420 4000 3 1
						410 430 3500 4 2
						420 440 2000 4 3>;

		oplus,plc_strategy-data = <&oplus_ufcs_step_strategy &cp_2t1_simple_strategy>;
		oplus,plc_strategy-names = "default", "third";

		ufcs_oplus_lcf_strategy {
			oplus,temp_type = <OPLUS_STRATEGY_USE_SHELL_TEMP>;
			oplus,temp_range = <0 50 120 160 210 380 440>;

			strategy_temp_range_curves {
				strategy_temp_range_t0 =	<356  4530 0
								 331  4520 0
								 306  4510 0
								 281  4500 0
								 256  4490 1>;
				strategy_temp_range_t1 =	<850  4550 0
								 800  4545 0
								 750  4530 0
								 650  4520 0
								 550  4510 1>;
				strategy_temp_range_t2 =	<1050 4550 0
								 1000 4545 0
								 900  4530 0
								 800  4520 0
								 650  4510 1>;
				strategy_temp_range_t3 =	<1250 4550 0
								 1200 4545 0
								 1100 4530 0
								 1000 4520 0
								 850  4510 1>;
				strategy_temp_range_t4 =	<1450 4550 0
								 1400 4545 0
								 1300 4530 0
								 1200 4520 0
								 1050 4510 1>;
				strategy_temp_range_t5 =	<2100 4546 0
								 1900 4543 0
								 1600 4535 0
								 1300 4525 0
								 1000 4515 1>;
			};
		};

		ufcs_third_lcf_strategy {
			oplus,temp_type = <OPLUS_STRATEGY_USE_SHELL_TEMP>;
			oplus,temp_range = <0 50 120 160 210 380 440>;

			strategy_temp_range_curves {
				strategy_temp_range_t0 =	<356  4530 0
								 331  4520 0
								 306  4510 0
								 281  4500 0
								 256  4490 1>;
				strategy_temp_range_t1 =	<850  4550 0
								 800  4545 0
								 750  4530 0
								 650  4520 0
								 550  4510 1>;
				strategy_temp_range_t2 =	<1050 4550 0
								 1000 4545 0
								 900  4530 0
								 800  4520 0
								 650  4510 1>;
				strategy_temp_range_t3 =	<1250 4550 0
								 1200 4545 0
								 1100 4530 0
								 1000 4520 0
								 850  4510 1>;
				strategy_temp_range_t4 =	<1450 4550 0
								 1400 4545 0
								 1300 4530 0
								 1200 4520 0
								 1050 4510 1>;
				strategy_temp_range_t5 =	<2100 4546 0
								 1900 4543 0
								 1600 4535 0
								 1300 4525 0
								 1000 4515 1>;
			};
		};

		ufcs_charge_third_strategy {
			oplus,temp_type = <OPLUS_STRATEGY_USE_SHELL_TEMP>;
			oplus,soc_range = <0 20 35 55 75 85 95>;
			oplus,temp_range = <0 50 120 160 210 350 440 510>;
			oplus,iterm = <2000 /* 0 ~ 5 */
				       2000 /* 5 ~ 12 */
				       2000 /* 12 ~ 16 */
				       2000 /* 16 ~ 21 */
				       2000 /* 21 ~ 35 */
				       2400 /* 35 ~ 44 */
				       2000 /* 44 ~ 51 */
					>;

			strategy_soc_range_min { /* 0 ~ 20 */
				strategy_temp_little_cold =	<11000 4070 1100 0 0
								 11000 4080 1000 1 0>;
				strategy_temp_cool =		<11000 4040 1650 0 0
								 11000 4040 1500 0 0
								 11000 4050 1000 1 0>;
				strategy_temp_little_cool =	<11000 4050 2700 0 0
								 11000 4050 2500 0 0
								 11000 4050 2000 0 0
								 11000 4200 1650 (CURVE_CV | CURVE_EXIT) 0>;
				strategy_temp_little_cool_high =<11000 4050 4000 0 0
								 11000 4050 3500 0 0
								 11000 4050 3000 0 0
								 11000 4150 2700 CURVE_CV 0
								 11000 4550 1000 (CURVE_CV | CURVE_EXIT) 0>;
				strategy_temp_normal_low =	<11000 4550 4000 (CURVE_CV | CURVE_EXIT) 0>;
				strategy_temp_normal_high =	<11000 4550 4000 (CURVE_CV | CURVE_EXIT) 0>;
				strategy_temp_warm =		<11000 4120 2000 0 0
								 11000 4120 1500 0 0
								 11000 4130 1000 1 0>;
			};
			strategy_soc_range_low { /* 21 ~ 35 */
				strategy_temp_little_cold =	<11000 4070 1100 0 0
								 11000 4080 1000 1 0>;
				strategy_temp_cool =		<11000 4040 1650 0 0
								 11000 4040 1500 0 0
								 11000 4050 1000 1 0>;
				strategy_temp_little_cool =	<11000 4050 2700 0 0
								 11000 4050 2500 0 0
								 11000 4050 2000 0 0
								 11000 4200 1650 (CURVE_CV | CURVE_EXIT) 0>;
				strategy_temp_little_cool_high =<11000 4050 4000 0 0
								 11000 4050 3500 0 0
								 11000 4050 3000 0 0
								 11000 4150 2700 CURVE_CV 0
								 11000 4550 1000 (CURVE_CV | CURVE_EXIT) 0>;
				strategy_temp_normal_low =	<11000 4550 4000 (CURVE_CV | CURVE_EXIT) 0>;
				strategy_temp_normal_high =	<11000 4550 4000 (CURVE_CV | CURVE_EXIT) 0>;
				strategy_temp_warm =		<11000 4120 2000 0 0
								 11000 4120 1500 0 0
								 11000 4130 1000 1 0>;
			};
			strategy_soc_range_mid_low { /* 36 ~ 55 */
				strategy_temp_little_cold =	<11000 4070 1100 0 0
								 11000 4080 1000 1 0>;
				strategy_temp_cool =		<11000 4040 1650 0 0
								 11000 4040 1500 0 0
								 11000 4050 1000 1 0>;
				strategy_temp_little_cool =	<11000 4050 2700 0 0
								 11000 4050 2500 0 0
								 11000 4050 2000 0 0
								 11000 4200 1650 (CURVE_CV | CURVE_EXIT) 0>;
				strategy_temp_little_cool_high =<11000 4050 4000 0 0
								 11000 4050 3500 0 0
								 11000 4050 3000 0 0
								 11000 4150 2700 CURVE_CV 0
								 11000 4550 1000 (CURVE_CV | CURVE_EXIT) 0>;
				strategy_temp_normal_low =	<11000 4550 4000 (CURVE_CV | CURVE_EXIT) 0>;
				strategy_temp_normal_high =	<11000 4550 4000 (CURVE_CV | CURVE_EXIT) 0>;
				strategy_temp_warm =		<11000 4120 2000 0 0
								 11000 4120 1500 0 0
								 11000 4130 1000 1 0>;
			};
			strategy_soc_range_mid { /* 56 ~ 75*/
				strategy_temp_little_cold =	<11000 4070 1100 0 0
								 11000 4080 1000 1 0>;
				strategy_temp_cool =		<11000 4040 1650 0 0
								 11000 4040 1500 0 0
								 11000 4050 1000 1 0>;
				strategy_temp_little_cool =	<11000 4050 2700 0 0
								 11000 4050 2500 0 0
								 11000 4050 2000 0 0
								 11000 4200 1650 (CURVE_CV | CURVE_EXIT) 0>;
				strategy_temp_little_cool_high =<11000 4050 4000 0 0
								 11000 4050 3500 0 0
								 11000 4050 3000 0 0
								 11000 4150 2700 CURVE_CV 0
								 11000 4550 1000 (CURVE_CV | CURVE_EXIT) 0>;
				strategy_temp_normal_low =	<11000 4550 4000 (CURVE_CV | CURVE_EXIT) 0>;
				strategy_temp_normal_high =	<11000 4550 4000 (CURVE_CV | CURVE_EXIT) 0>;
				strategy_temp_warm =		<11000 4120 2000 0 0
								 11000 4120 1500 0 0
								 11000 4130 1000 1 0>;
			};
			strategy_soc_range_mid_high { /* 76 ~ 85 */
				strategy_temp_little_cold =	<11000 4070 1100 0 0
								 11000 4080 1000 1 0>;
				strategy_temp_cool =		<11000 4040 1650 0 0
								 11000 4040 1500 0 0
								 11000 4050 1000 1 0>;
				strategy_temp_little_cool =	<11000 4050 2500 0 0
								 11000 4050 2000 0 0
								 11000 4200 1650 (CURVE_CV | CURVE_EXIT) 0>;
				strategy_temp_little_cool_high =<11000 4050 3000 0 0
								 11000 4150 2700 CURVE_CV 0
								 11000 4550 1000 (CURVE_CV | CURVE_EXIT) 0>;
				strategy_temp_normal_low =	<11000 4550 4000 (CURVE_CV | CURVE_EXIT) 0>;
				strategy_temp_normal_high =	<11000 4550 4000 (CURVE_CV | CURVE_EXIT) 0>;
				strategy_temp_warm =		<11000 4120 2000 0 0
								 11000 4120 1500 0 0
								 11000 4130 1000 1 0>;
			};
			strategy_soc_range_high { /* 86 ~ 90 */
				strategy_temp_little_cold =	<11000 4070 1100 0 0
								 11000 4080 1000 1 0>;
				strategy_temp_cool =		<11000 4040 1500 0 0
								 11000 4050 1000 1 0>;
				strategy_temp_little_cool =	<11000 4050 2000 0 0
								 11000 4200 1650 (CURVE_CV | CURVE_EXIT) 0>;
				strategy_temp_little_cool_high =<11000 4150 2500 CURVE_CV 0
								 11000 4550 1000 (CURVE_CV | CURVE_EXIT) 0>;
				strategy_temp_normal_low =	<11000 4550 3000 (CURVE_CV | CURVE_EXIT) 0>;
				strategy_temp_normal_high =	<11000 4550 3000 (CURVE_CV | CURVE_EXIT) 0>;
				strategy_temp_warm =		<11000 4120 2000 0 0
								 11000 4120 1500 0 0
								 11000 4130 1000 1 0>;
			};
		};

		ufcs_charge_oplus_strategy {
			oplus,temp_type = <OPLUS_STRATEGY_USE_SHELL_TEMP>;
			oplus,soc_range = <0 20 35 55 75 85 95>;
			oplus,temp_range = <0 50 120 160 210 350 440 510>;
			oplus,iterm = <2000 /* 0 ~ 5 */
				       2000 /* 5 ~ 12 */
				       2000 /* 12 ~ 16 */
				       2000 /* 16 ~ 21 */
				       2000 /* 21 ~ 35 */
				       2400 /* 35 ~ 44 */
				       2000 /* 44 ~ 51 */
					>;

			strategy_soc_range_min { /* 0 ~ 20 */
				strategy_temp_little_cold =	<11000 4070 1100 0 0
								 11000 4080 1000 1 0>;
				strategy_temp_cool =		<11000 4040 1650 0 0
								 11000 4040 1500 0 0
								 11000 4050 1000 1 0>;
				strategy_temp_little_cool =	<11000 4050 2700 0 0
								 11000 4050 2500 0 0
								 11000 4050 2000 0 0
								 11000 4200 1650 (CURVE_CV | CURVE_EXIT) 0>;
				strategy_temp_little_cool_high =<11000 4050 4050 0 0
								 11000 4050 4000 0 0
								 11000 4050 3500 0 0
								 11000 4050 3000 0 0
								 11000 4150 2700 CURVE_CV 0
								 11000 4550 1000 (CURVE_CV | CURVE_EXIT) 0>;
				strategy_temp_normal_low =	<11000 4030 9100 0 60
								 11000 4030 7500 0 0
								 11000 4060 7400 0 270
								 11000 4060 7000 0 0
								 11000 4060 6000 0 0
								 11000 4160 5700 CURVE_CV 510
								 11000 4380 5050 CURVE_CV 0
								 11000 4510 4400 CURVE_CV 0
								 11000 4550 4200 (CURVE_CV | CURVE_EXIT) 0>;
				strategy_temp_normal_high =	<11000 4030 9100 0 60
								 11000 4030 7500 0 0
								 11000 4060 7400 0 270
								 11000 4060 7000 0 0
								 11000 4060 6000 0 0
								 11000 4160 5700 CURVE_CV 510
								 11000 4380 5050 CURVE_CV 0
								 11000 4510 4400 CURVE_CV 0
								 11000 4550 4200 (CURVE_CV | CURVE_EXIT) 0>;
				strategy_temp_warm =		<11000 4120 2000 0 0
								 11000 4120 1500 0 0
								 11000 4130 1000 1 0>;
			};
			strategy_soc_range_low { /* 21 ~ 35 */
				strategy_temp_little_cold =	<11000 4070 1100 0 0
								 11000 4080 1000 1 0>;
				strategy_temp_cool =		<11000 4040 1650 0 0
								 11000 4040 1500 0 0
								 11000 4050 1000 1 0>;
				strategy_temp_little_cool =	<11000 4050 2700 0 0
								 11000 4050 2500 0 0
								 11000 4050 2000 0 0
								 11000 4200 1650 (CURVE_CV | CURVE_EXIT) 0>;
				strategy_temp_little_cool_high =<11000 4050 4050 0 0
								 11000 4050 4000 0 0
								 11000 4050 3500 0 0
								 11000 4050 3000 0 0
								 11000 4150 2700 CURVE_CV 0
								 11000 4550 1000 (CURVE_CV | CURVE_EXIT) 0>;
				strategy_temp_normal_low =	<11000 4030 9100 0 60
								 11000 4030 7500 0 0
								 11000 4060 7400 0 270
								 11000 4060 7000 0 0
								 11000 4060 6000 0 0
								 11000 4160 5700 CURVE_CV 510
								 11000 4380 5050 CURVE_CV 0
								 11000 4510 4400 CURVE_CV 0
								 11000 4550 4200 (CURVE_CV | CURVE_EXIT) 0>;
				strategy_temp_normal_high =	<11000 4030 9100 0 60
								 11000 4030 7500 0 0
								 11000 4060 7400 0 270
								 11000 4060 7000 0 0
								 11000 4060 6000 0 0
								 11000 4160 5700 CURVE_CV 510
								 11000 4380 5050 CURVE_CV 0
								 11000 4510 4400 CURVE_CV 0
								 11000 4550 4200 (CURVE_CV | CURVE_EXIT) 0>;
				strategy_temp_warm =		<11000 4120 2000 0 0
								 11000 4120 1500 0 0
								 11000 4130 1000 1 0>;
			};
			strategy_soc_range_mid_low { /* 36 ~ 55 */
				strategy_temp_little_cold =	<11000 4070 1100 0 0
								 11000 4080 1000 1 0>;
				strategy_temp_cool =		<11000 4040 1650 0 0
								 11000 4040 1500 0 0
								 11000 4050 1000 1 0>;
				strategy_temp_little_cool =	<11000 4050 2700 0 0
								 11000 4050 2500 0 0
								 11000 4050 2000 0 0
								 11000 4200 1650 (CURVE_CV | CURVE_EXIT) 0>;
				strategy_temp_little_cool_high =<11000 4050 4050 0 0
								 11000 4050 4000 0 0
								 11000 4050 3500 0 0
								 11000 4050 3000 0 0
								 11000 4150 2700 CURVE_CV 0
								 11000 4550 1000 (CURVE_CV | CURVE_EXIT) 0>;
				strategy_temp_normal_low =	<11000 4030 9100 0 60
								 11000 4030 7500 0 0
								 11000 4060 7400 0 270
								 11000 4060 7000 0 0
								 11000 4060 6000 0 0
								 11000 4160 5700 CURVE_CV 510
								 11000 4380 5050 CURVE_CV 0
								 11000 4510 4400 CURVE_CV 0
								 11000 4550 4200 (CURVE_CV | CURVE_EXIT) 0>;
				strategy_temp_normal_high =	<11000 4030 9100 0 60
								 11000 4030 7500 0 0
								 11000 4060 7400 0 270
								 11000 4060 7000 0 0
								 11000 4060 6000 0 0
								 11000 4160 5700 CURVE_CV 510
								 11000 4380 5050 CURVE_CV 0
								 11000 4510 4400 CURVE_CV 0
								 11000 4550 4200 (CURVE_CV | CURVE_EXIT) 0>;
				strategy_temp_warm =		<11000 4120 2000 0 0
								 11000 4120 1500 0 0
								 11000 4130 1000 1 0>;
			};
			strategy_soc_range_mid { /* 56 ~ 75 */
				strategy_temp_little_cold =	<11000 4070 1100 0 0
								 11000 4080 1000 1 0>;
				strategy_temp_cool =		<11000 4040 1650 0 0
								 11000 4040 1500 0 0
								 11000 4050 1000 1 0>;
				strategy_temp_little_cool =	<11000 4050 2700 0 0
								 11000 4050 2500 0 0
								 11000 4050 2000 0 0
								 11000 4200 1650 (CURVE_CV | CURVE_EXIT) 0>;
				strategy_temp_little_cool_high =<11000 4050 4050 0 0
								 11000 4050 4000 0 0
								 11000 4050 3500 0 0
								 11000 4050 3000 0 0
								 11000 4150 2700 CURVE_CV 0
								 11000 4550 1000 (CURVE_CV | CURVE_EXIT) 0>;
				strategy_temp_normal_low =	<11000 4060 6000 0 0
								 11000 4160 5700 CURVE_CV 510
								 11000 4380 5050 CURVE_CV 0
								 11000 4510 4400 CURVE_CV 0
								 11000 4550 4200 (CURVE_CV | CURVE_EXIT) 0>;
				strategy_temp_normal_high =	<11000 4060 7000 0 0
								 11000 4060 6000 0 0
								 11000 4160 5700 CURVE_CV 510
								 11000 4380 5050 CURVE_CV 0
								 11000 4510 4400 CURVE_CV 0
								 11000 4550 4200 (CURVE_CV | CURVE_EXIT) 0>;
				strategy_temp_warm =		<11000 4120 2000 0 0
								 11000 4120 1500 0 0
								 11000 4130 1000 1 0>;
			};
			strategy_soc_range_mid_high { /* 76 ~ 85 */
				strategy_temp_little_cold =	<11000 4070 1100 0 0
								 11000 4080 1000 1 0>;
				strategy_temp_cool =		<11000 4040 1650 0 0
								 11000 4040 1500 0 0
								 11000 4050 1000 1 0>;
				strategy_temp_little_cool =	<11000 4050 2700 0 0
								 11000 4050 2500 0 0
								 11000 4050 2000 0 0
								 11000 4200 1650 (CURVE_CV | CURVE_EXIT) 0>;
				strategy_temp_little_cool_high =<11000 4050 4000 0 0
								 11000 4050 3500 0 0
								 11000 4050 3000 0 0
								 11000 4150 2700 CURVE_CV 0
								 11000 4550 1000 (CURVE_CV | CURVE_EXIT) 0>;
				strategy_temp_normal_low =	<11000 4380 5000 CURVE_CV 0
								 11000 4510 4400 CURVE_CV 0
								 11000 4550 4200 (CURVE_CV | CURVE_EXIT) 0>;
				strategy_temp_normal_high =	<11000 4060 6000 0 0
								 11000 4160 5700 CURVE_CV 510
								 11000 4380 5050 CURVE_CV 0
								 11000 4510 4400 CURVE_CV 0
								 11000 4550 4200 (CURVE_CV | CURVE_EXIT) 0>;
				strategy_temp_warm =		<11000 4120 2000 0 0
								 11000 4120 1500 0 0
								 11000 4130 1000 1 0>;
			};
			strategy_soc_range_high { /* 86 ~ 90 */
				strategy_temp_little_cold =	<11000 4070 1100 0 0
								 11000 4080 1000 1 0>;
				strategy_temp_cool =		<11000 4040 1500 0 0
								 11000 4050 1000 1 0>;
				strategy_temp_little_cool =	<11000 4050 2000 0 0
								 11000 4200 1650 (CURVE_CV | CURVE_EXIT) 0>;
				strategy_temp_little_cool_high =<11000 4050 3000 0 0
								 11000 4150 2700 CURVE_CV 0
								 11000 4550 1000 (CURVE_CV | CURVE_EXIT) 0>;
				strategy_temp_normal_low =	<11000 4550 4000 (CURVE_CV | CURVE_EXIT) 0>;
				strategy_temp_normal_high =	<11000 4380 5000 CURVE_CV 0
								 11000 4510 4400 CURVE_CV 0
								 11000 4550 4200 (CURVE_CV | CURVE_EXIT) 0>;
				strategy_temp_warm =		<11000 4120 2000 0 0
								 11000 4120 1500 0 0
								 11000 4130 1000 1 0>;
			};
		};

		oplus,impedance_node {
			ufcs_input_impedance: ufcs_input_impedance {
				node_name = "ufcs_input";
				default_impedance_mohm = <0>;
				default_curr_ma = <9100>;
				current_drop_table = <
					125 10000
					130 8000
					190 5000
					250 4000
					340 3000
					380 2000
					480 0
				>;
			};
		};
	};

	oplus_ufcs_impedance_check: oplus,ufcs_impedance_check {
		compatible = "oplus,impedance_check";

		oplus,impedance_unit {
			oplus_ufcs_impedance_unit: oplus,ufcs_impedance_unit {
				uint_name = "ufcs";
				default_curr_ma = <9100>;
				impedance_node = <&ufcs_input_impedance>;
			};
		};
	};
};
/*for ufcs config*/

/*for pps config*/
&soc {
	oplus_virtual_pps: oplus,virtual_pps {
		compatible = "oplus,virtual_pps";

		oplus,ic_type = <OPLUS_CHG_IC_VIRTUAL_PPS>;
		oplus,ic_index = <0>;
		oplus,pps_ic = <&oplus_adsp_pps>;
	};

	oplus_pps_charge: oplus,pps_charge {
		compatible = "oplus,pps_charge";
		oplus,pps_ic = <&oplus_virtual_pps>;
		oplus,cp_ic = <&oplus_virtual_cp>;
		oplus,dpdm_switch_ic = <&oplus_virtual_dpdm_switch>;

		oplus,target_vbus_mv = <11000>;
		oplus,curr_max_ma = <5000>;
		oplus,curr_max_ma_percent = <2500 /* 75% ibus */
					     1000 /* 85% ibus */>;
		oplus,lift_vbus_use_cpvout;
		oplus,process_close_cp_item;

		oplus,pps_warm_allow_vol = <4000>;
		oplus,pps_warm_allow_soc = <55>;
		oplus,pps_strategy_normal_current = <5000>;
		oplus,pps_over_high_or_low_current = <5000>;
		oplus,pps_timeout_third = <18308>;
		oplus,pps_timeout_oplus = <18308>;
		oplus,pps_ibat_over_third = <11400>;
		oplus,pps_ibat_over_oplus = <11400>;
		oplus,pps_full_cool_sw_vbat = <4050>;
		oplus,pps_full_normal_sw_vbat = <4550>;
		oplus,pps_full_normal_hw_vbat = <4560>;
		oplus,pps_full_warm_vbat = <4130>;
		oplus,pps_full_cool_sw_vbat_third = <4050>;
		oplus,pps_full_normal_sw_vbat_third= <4550>;
		oplus,pps_full_normal_hw_vbat_third = <4560>;
		oplus,pps_strategy_batt_high_temp = <410 430 435 400 425 430>;
		oplus,pps_strategy_high_current = <5000 3000 2000 5000 5000 5000>;
		oplus,pps_little_cool_high_temp = <210>;
		oplus,curve_strategy_name = "pps_ufcs_curve_v2";
		oplus,pps_charge_strategy_soc = <0 20 35 55 75 85 90>;
		oplus,pps_charge_strategy_temp = <50 50 120 160 350 440 510>;
		oplus,pps_full_recheck_temp = <210>;
		oplus,pps_low_temp = <50>;
		oplus,temperature_strategy_name = "cgcl";
		oplus,temperature_strategy_data = <OPLUS_STRATEGY_USE_SHELL_TEMP
						0   385 7300 1 0
						375 405 5000 2 0
						395 420 4000 3 1
						410 430 3500 4 2
						420 440 2000 4 3>;

		oplus,plc_strategy-data = <&cp_2t1_simple_strategy>;
		oplus,plc_strategy-names = "default";

		pps_oplus_lcf_strategy {
			oplus,temp_type = <OPLUS_STRATEGY_USE_SHELL_TEMP>;
			oplus,temp_range = <0 50 120 160 210 380 440>;

			strategy_temp_range_curves {
				strategy_temp_range_t0 =	<356  4530 0
								 331  4520 0
								 306  4510 0
								 281  4500 0
								 256  4490 1>;
				strategy_temp_range_t1 =	<850  4550 0
								 800  4545 0
								 750  4530 0
								 650  4520 0
								 550  4510 1>;
				strategy_temp_range_t2 =	<1050 4550 0
								 1000 4545 0
								 900  4530 0
								 800  4520 0
								 650  4510 1>;
				strategy_temp_range_t3 =	<1250 4550 0
								 1200 4545 0
								 1100 4530 0
								 1000 4520 0
								 850  4510 1>;
				strategy_temp_range_t4 =	<1450 4550 0
								 1400 4545 0
								 1300 4530 0
								 1200 4520 0
								 1050 4510 1>;
				strategy_temp_range_t5 =	<2100 4546 0
								 1900 4543 0
								 1600 4535 0
								 1300 4525 0
								 1000 4515 1>;
			};
		};

		pps_third_lcf_strategy {
			oplus,temp_type = <OPLUS_STRATEGY_USE_SHELL_TEMP>;
			oplus,temp_range = <0 50 120 160 210 380 440>;

			strategy_temp_range_curves {
				strategy_temp_range_t0 =	<356  4530 0
								 331  4520 0
								 306  4510 0
								 281  4500 0
								 256  4490 1>;
				strategy_temp_range_t1 =	<850  4550 0
								 800  4545 0
								 750  4530 0
								 650  4520 0
								 550  4510 1>;
				strategy_temp_range_t2 =	<1050 4550 0
								 1000 4545 0
								 900  4530 0
								 800  4520 0
								 650  4510 1>;
				strategy_temp_range_t3 =	<1250 4550 0
								 1200 4545 0
								 1100 4530 0
								 1000 4520 0
								 850  4510 1>;
				strategy_temp_range_t4 =	<1450 4550 0
								 1400 4545 0
								 1300 4530 0
								 1200 4520 0
								 1050 4510 1>;
				strategy_temp_range_t5 =	<2100 4546 0
								 1900 4543 0
								 1600 4535 0
								 1300 4525 0
								 1000 4515 1>;
			};
		};

		pps_charge_third_strategy {
			oplus,temp_type = <OPLUS_STRATEGY_USE_SHELL_TEMP>;
			oplus,soc_range = <0 20 35 55 75 85 90>;
			oplus,temp_range = <0 50 120 160 210 350 440 510>;

			strategy_soc_range_min { /* 0 ~ 20 */
				strategy_temp_little_cold =	<11000 4070 1100 0 0
								 11000 4080 1000 1 0>;
				strategy_temp_cool =		<11000 4040 1650 0 0
								 11000 4040 1500 0 0
								 11000 4050 1000 1 0>;
				strategy_temp_little_cool =	<11000 4050 2700 0 0
								 11000 4050 2500 0 0
								 11000 4050 2000 0 0
								 11000 4190 1650 0 0
								 11000 4190 1500 0 0
								 11000 4200 1000 1 0>;
				strategy_temp_little_cool_high =<11000 4050 4050 0 0
								 11000 4050 4000 0 0
								 11000 4050 3500 0 0
								 11000 4050 3000 0 0
								 11000 4150 2700 0 0
								 11000 4150 2500 0 0
								 11000 4150 2000 0 0
								 11000 4150 1500 0 0
								 11000 4550 1000 1 0>;
				strategy_temp_normal_low =	<11000 4380 5000 0 0
								 11000 4380 4500 0 0
								 11000 4510 4400 0 0
								 11000 4540 4200 0 0
								 11000 4540 4000 0 0
								 11000 4540 3500 0 0
								 11000 4540 3000 0 0
								 11000 4540 2500 0 0
								 11000 4540 2000 0 0
								 11000 4540 1500 0 0
								 11000 4550 1000 1 0>;
				strategy_temp_normal_high =	<11000 4380 5000 0 0
								 11000 4380 4500 0 0
								 11000 4510 4400 0 0
								 11000 4540 4200 0 0
								 11000 4540 4000 0 0
								 11000 4540 3500 0 0
								 11000 4540 3000 0 0
								 11000 4540 2500 0 0
								 11000 4540 2000 0 0
								 11000 4540 1500 0 0
								 11000 4550 1200 1 0>;
				strategy_temp_warm =		<11000 4120 2000 0 0
								 11000 4120 1500 0 0
								 11000 4130 1000 1 0>;
			};
			strategy_soc_range_low { /* 21 ~ 35 */
				strategy_temp_little_cold =	<11000 4070 1100 0 0
								 11000 4080 1000 1 0>;
				strategy_temp_cool =		<11000 4040 1650 0 0
								 11000 4040 1500 0 0
								 11000 4050 1000 1 0>;
				strategy_temp_little_cool =	<11000 4050 2700 0 0
								 11000 4050 2500 0 0
								 11000 4050 2000 0 0
								 11000 4190 1650 0 0
								 11000 4190 1500 0 0
								 11000 4200 1000 1 0>;
				strategy_temp_little_cool_high =<11000 4050 4050 0 0
								 11000 4050 4000 0 0
								 11000 4050 3500 0 0
								 11000 4050 3000 0 0
								 11000 4150 2700 0 0
								 11000 4150 2500 0 0
								 11000 4150 2000 0 0
								 11000 4150 1500 0 0
								 11000 4550 1000 1 0>;
				strategy_temp_normal_low =	<11000 4380 5000 0 0
								 11000 4380 4500 0 0
								 11000 4510 4400 0 0
								 11000 4540 4200 0 0
								 11000 4540 4000 0 0
								 11000 4540 3500 0 0
								 11000 4540 3000 0 0
								 11000 4540 2500 0 0
								 11000 4540 2000 0 0
								 11000 4540 1500 0 0
								 11000 4550 1000 1 0>;
				strategy_temp_normal_high =	<11000 4380 5000 0 0
								 11000 4380 4500 0 0
								 11000 4510 4400 0 0
								 11000 4540 4200 0 0
								 11000 4540 4000 0 0
								 11000 4540 3500 0 0
								 11000 4540 3000 0 0
								 11000 4540 2500 0 0
								 11000 4540 2000 0 0
								 11000 4540 1500 0 0
								 11000 4550 1200 1 0>;
				strategy_temp_warm =		<11000 4120 2000 0 0
								 11000 4120 1500 0 0
								 11000 4130 1000 1 0>;
			};
			strategy_soc_range_mid_low { /* 36 ~ 55 */
				strategy_temp_little_cold =	<11000 4070 1100 0 0
								 11000 4080 1000 1 0>;
				strategy_temp_cool =		<11000 4040 1650 0 0
								 11000 4040 1500 0 0
								 11000 4050 1000 1 0>;
				strategy_temp_little_cool =	<11000 4050 2700 0 0
								 11000 4050 2500 0 0
								 11000 4050 2000 0 0
								 11000 4190 1650 0 0
								 11000 4190 1500 0 0
								 11000 4200 1000 1 0>;
				strategy_temp_little_cool_high =<11000 4050 4050 0 0
								 11000 4050 4000 0 0
								 11000 4050 3500 0 0
								 11000 4050 3000 0 0
								 11000 4150 2700 0 0
								 11000 4150 2500 0 0
								 11000 4150 2000 0 0
								 11000 4150 1500 0 0
								 11000 4550 1000 1 0>;
				strategy_temp_normal_low =	<11000 4380 5000 0 0
								 11000 4380 4500 0 0
								 11000 4510 4400 0 0
								 11000 4540 4200 0 0
								 11000 4540 4000 0 0
								 11000 4540 3500 0 0
								 11000 4540 3000 0 0
								 11000 4540 2500 0 0
								 11000 4540 2000 0 0
								 11000 4540 1500 0 0
								 11000 4550 1000 1 0>;
				strategy_temp_normal_high =	<11000 4380 5000 0 0
								 11000 4380 4500 0 0
								 11000 4510 4400 0 0
								 11000 4540 4200 0 0
								 11000 4540 4000 0 0
								 11000 4540 3500 0 0
								 11000 4540 3000 0 0
								 11000 4540 2500 0 0
								 11000 4540 2000 0 0
								 11000 4540 1500 0 0
								 11000 4550 1200 1 0>;
				strategy_temp_warm =		<11000 4120 2000 0 0
								 11000 4120 1500 0 0
								 11000 4130 1000 1 0>;
			};
			strategy_soc_range_mid { /* 56 ~ 75*/
				strategy_temp_little_cold =	<11000 4070 1100 0 0
								 11000 4080 1000 1 0>;
				strategy_temp_cool =		<11000 4040 1650 0 0
								 11000 4040 1500 0 0
								 11000 4050 1000 1 0>;
				strategy_temp_little_cool =	<11000 4050 2700 0 0
								 11000 4050 2500 0 0
								 11000 4050 2000 0 0
								 11000 4190 1650 0 0
								 11000 4190 1500 0 0
								 11000 4200 1000 1 0>;
				strategy_temp_little_cool_high =<11000 4050 4000 0 0
								 11000 4050 3500 0 0
								 11000 4050 3000 0 0
								 11000 4150 2700 0 0
								 11000 4150 2500 0 0
								 11000 4150 2000 0 0
								 11000 4150 1500 0 0
								 11000 4550 1000 1 0>;
				strategy_temp_normal_low =	<11000 4380 4500 0 0
								 11000 4510 4400 0 0
								 11000 4540 4200 0 0
								 11000 4540 4000 0 0
								 11000 4540 3500 0 0
								 11000 4540 3000 0 0
								 11000 4540 2500 0 0
								 11000 4540 2000 0 0
								 11000 4540 1500 0 0
								 11000 4550 1000 1 0>;
				strategy_temp_normal_high =	<11000 4380 5000 0 0
								 11000 4380 4500 0 0
								 11000 4510 4400 0 0
								 11000 4540 4200 0 0
								 11000 4540 4000 0 0
								 11000 4540 3500 0 0
								 11000 4540 3000 0 0
								 11000 4540 2500 0 0
								 11000 4540 2000 0 0
								 11000 4540 1500 0 0
								 11000 4550 1200 1 0>;
				strategy_temp_warm =		<11000 4120 2000 0 0
								 11000 4120 1500 0 0
								 11000 4130 1000 1 0>;
			};
			strategy_soc_range_mid_high { /* 76 ~ 85 */
				strategy_temp_little_cold =	<11000 4070 1100 0 0
								 11000 4080 1000 1 0>;
				strategy_temp_cool =		<11000 4040 1650 0 0
								 11000 4040 1500 0 0
								 11000 4050 1000 1 0>;
				strategy_temp_little_cool =	<11000 4050 2500 0 0
								 11000 4050 2000 0 0
								 11000 4190 1650 0 0
								 11000 4190 1500 0 0
								 11000 4200 1000 1 0>;
				strategy_temp_little_cool_high =<11000 4050 3000 0 0
								 11000 4150 2700 0 0
								 11000 4150 2500 0 0
								 11000 4150 2000 0 0
								 11000 4150 1500 0 0
								 11000 4550 1000 1 0>;
				strategy_temp_normal_low =	<11000 4540 4000 0 0
								 11000 4540 3500 0 0
								 11000 4540 3000 0 0
								 11000 4540 2500 0 0
								 11000 4540 2000 0 0
								 11000 4540 1500 0 0
								 11000 4550 1000 1 0>;
				strategy_temp_normal_high =	<11000 4540 4000 0 0
								 11000 4540 3500 0 0
								 11000 4540 3000 0 0
								 11000 4540 2500 0 0
								 11000 4540 2000 0 0
								 11000 4540 1500 0 0
								 11000 4550 1200 1 0>;
				strategy_temp_warm =		<11000 4120 2000 0 0
								 11000 4120 1500 0 0
								 11000 4130 1000 1 0>;
			};
			strategy_soc_range_high { /* 86 ~ 90 */
				strategy_temp_little_cold =	<11000 4070 1100 0 0
								 11000 4080 1000 1 0>;
				strategy_temp_cool =		<11000 4040 1500 0 0
								 11000 4050 1000 1 0>;
				strategy_temp_little_cool =	<11000 4050 2000 0 0
								 11000 4190 1650 0 0
								 11000 4190 1500 0 0
								 11000 4200 1000 1 0>;
				strategy_temp_little_cool_high =<11000 4150 2500 0 0
								 11000 4150 2000 0 0
								 11000 4150 1500 0 0
								 11000 4550 1000 1 0>;
				strategy_temp_normal_low =	<11000 4540 3000 0 0
								 11000 4540 2500 0 0
								 11000 4540 2000 0 0
								 11000 4540 1500 0 0
								 11000 4550 1000 1 0>;
				strategy_temp_normal_high =	<11000 4540 3000 0 0
								 11000 4540 2500 0 0
								 11000 4540 2000 0 0
								 11000 4540 1500 0 0
								 11000 4550 1200 1 0>;
				strategy_temp_warm =		<11000 4120 2000 0 0
								 11000 4120 1500 0 0
								 11000 4130 1000 1 0>;
			};
		};

		pps_charge_oplus_strategy {
			oplus,temp_type = <OPLUS_STRATEGY_USE_SHELL_TEMP>;
			oplus,soc_range = <0 20 35 55 75 85 90>;
			oplus,temp_range = <0 50 120 160 210 350 440 510>;

			strategy_soc_range_min { /* 0 ~ 20 */
				strategy_temp_little_cold =	<11000 4070 1100 0 0
								 11000 4080 1000 1 0>;
				strategy_temp_cool =		<11000 4040 1650 0 0
								 11000 4040 1500 0 0
								 11000 4050 1000 1 0>;
				strategy_temp_little_cool =	<11000 4050 2700 0 0
								 11000 4050 2500 0 0
								 11000 4050 2000 0 0
								 11000 4190 1650 0 0
								 11000 4190 1500 0 0
								 11000 4200 1000 1 0>;
				strategy_temp_little_cool_high =<11000 4050 4050 0 0
								 11000 4050 4000 0 0
								 11000 4050 3500 0 0
								 11000 4050 3000 0 0
								 11000 4150 2700 0 0
								 11000 4150 2500 0 0
								 11000 4150 2000 0 0
								 11000 4150 1500 0 0
								 11000 4550 1000 1 0>;
				strategy_temp_normal_low =	<11000 4380 5000 0 0
								 11000 4380 4500 0 0
								 11000 4510 4400 0 0
								 11000 4540 4200 0 0
								 11000 4540 4000 0 0
								 11000 4540 3500 0 0
								 11000 4540 3000 0 0
								 11000 4540 2500 0 0
								 11000 4540 2000 0 0
								 11000 4540 1500 0 0
								 11000 4550 1000 1 0>;
				strategy_temp_normal_high =	<11000 4380 5000 0 0
								 11000 4380 4500 0 0
								 11000 4510 4400 0 0
								 11000 4540 4200 0 0
								 11000 4540 4000 0 0
								 11000 4540 3500 0 0
								 11000 4540 3000 0 0
								 11000 4540 2500 0 0
								 11000 4540 2000 0 0
								 11000 4540 1500 0 0
								 11000 4550 1200 1 0>;
				strategy_temp_warm =		<11000 4120 2000 0 0
								 11000 4120 1500 0 0
								 11000 4130 1000 1 0>;
			};
			strategy_soc_range_low { /* 21 ~ 35 */
				strategy_temp_little_cold =	<11000 4070 1100 0 0
								 11000 4080 1000 1 0>;
				strategy_temp_cool =		<11000 4040 1650 0 0
								 11000 4040 1500 0 0
								 11000 4050 1000 1 0>;
				strategy_temp_little_cool =	<11000 4050 2700 0 0
								 11000 4050 2500 0 0
								 11000 4050 2000 0 0
								 11000 4190 1650 0 0
								 11000 4190 1500 0 0
								 11000 4200 1000 1 0>;
				strategy_temp_little_cool_high =<11000 4050 4050 0 0
								 11000 4050 4000 0 0
								 11000 4050 3500 0 0
								 11000 4050 3000 0 0
								 11000 4150 2700 0 0
								 11000 4150 2500 0 0
								 11000 4150 2000 0 0
								 11000 4150 1500 0 0
								 11000 4550 1000 1 0>;
				strategy_temp_normal_low =	<11000 4380 5000 0 0
								 11000 4380 4500 0 0
								 11000 4510 4400 0 0
								 11000 4540 4200 0 0
								 11000 4540 4000 0 0
								 11000 4540 3500 0 0
								 11000 4540 3000 0 0
								 11000 4540 2500 0 0
								 11000 4540 2000 0 0
								 11000 4540 1500 0 0
								 11000 4550 1000 1 0>;
				strategy_temp_normal_high =	<11000 4380 5000 0 0
								 11000 4380 4500 0 0
								 11000 4510 4400 0 0
								 11000 4540 4200 0 0
								 11000 4540 4000 0 0
								 11000 4540 3500 0 0
								 11000 4540 3000 0 0
								 11000 4540 2500 0 0
								 11000 4540 2000 0 0
								 11000 4540 1500 0 0
								 11000 4550 1200 1 0>;
				strategy_temp_warm =		<11000 4120 2000 0 0
								 11000 4120 1500 0 0
								 11000 4130 1000 1 0>;
			};
			strategy_soc_range_mid_low { /* 36 ~ 55 */
				strategy_temp_little_cold =	<11000 4070 1100 0 0
								 11000 4080 1000 1 0>;
				strategy_temp_cool =		<11000 4040 1650 0 0
								 11000 4040 1500 0 0
								 11000 4050 1000 1 0>;
				strategy_temp_little_cool =	<11000 4050 2700 0 0
								 11000 4050 2500 0 0
								 11000 4050 2000 0 0
								 11000 4190 1650 0 0
								 11000 4190 1500 0 0
								 11000 4200 1000 1 0>;
				strategy_temp_little_cool_high =<11000 4050 4050 0 0
								 11000 4050 4000 0 0
								 11000 4050 3500 0 0
								 11000 4050 3000 0 0
								 11000 4150 2700 0 0
								 11000 4150 2500 0 0
								 11000 4150 2000 0 0
								 11000 4150 1500 0 0
								 11000 4550 1000 1 0>;
				strategy_temp_normal_low =	<11000 4380 5000 0 0
								 11000 4380 4500 0 0
								 11000 4510 4400 0 0
								 11000 4540 4200 0 0
								 11000 4540 4000 0 0
								 11000 4540 3500 0 0
								 11000 4540 3000 0 0
								 11000 4540 2500 0 0
								 11000 4540 2000 0 0
								 11000 4540 1500 0 0
								 11000 4550 1000 1 0>;
				strategy_temp_normal_high =	<11000 4380 5000 0 0
								 11000 4380 4500 0 0
								 11000 4510 4400 0 0
								 11000 4540 4200 0 0
								 11000 4540 4000 0 0
								 11000 4540 3500 0 0
								 11000 4540 3000 0 0
								 11000 4540 2500 0 0
								 11000 4540 2000 0 0
								 11000 4540 1500 0 0
								 11000 4550 1200 1 0>;
				strategy_temp_warm =		<11000 4120 2000 0 0
								 11000 4120 1500 0 0
								 11000 4130 1000 1 0>;
			};
			strategy_soc_range_mid { /* 56 ~ 75*/
				strategy_temp_little_cold =	<11000 4070 1100 0 0
								 11000 4080 1000 1 0>;
				strategy_temp_cool =		<11000 4040 1650 0 0
								 11000 4040 1500 0 0
								 11000 4050 1000 1 0>;
				strategy_temp_little_cool =	<11000 4050 2700 0 0
								 11000 4050 2500 0 0
								 11000 4050 2000 0 0
								 11000 4190 1650 0 0
								 11000 4190 1500 0 0
								 11000 4200 1000 1 0>;
				strategy_temp_little_cool_high =<11000 4050 4000 0 0
								 11000 4050 3500 0 0
								 11000 4050 3000 0 0
								 11000 4150 2700 0 0
								 11000 4150 2500 0 0
								 11000 4150 2000 0 0
								 11000 4150 1500 0 0
								 11000 4550 1000 1 0>;
				strategy_temp_normal_low =	<11000 4380 4500 0 0
								 11000 4510 4400 0 0
								 11000 4540 4200 0 0
								 11000 4540 4000 0 0
								 11000 4540 3500 0 0
								 11000 4540 3000 0 0
								 11000 4540 2500 0 0
								 11000 4540 2000 0 0
								 11000 4540 1500 0 0
								 11000 4550 1000 1 0>;
				strategy_temp_normal_high =	<11000 4380 5000 0 0
								 11000 4380 4500 0 0
								 11000 4510 4400 0 0
								 11000 4540 4200 0 0
								 11000 4540 4000 0 0
								 11000 4540 3500 0 0
								 11000 4540 3000 0 0
								 11000 4540 2500 0 0
								 11000 4540 2000 0 0
								 11000 4540 1500 0 0
								 11000 4550 1200 1 0>;
				strategy_temp_warm =		<11000 4120 2000 0 0
								 11000 4120 1500 0 0
								 11000 4130 1000 1 0>;
			};
			strategy_soc_range_mid_high { /* 76 ~ 85 */
				strategy_temp_little_cold =	<11000 4070 1100 0 0
								 11000 4080 1000 1 0>;
				strategy_temp_cool =		<11000 4040 1650 0 0
								 11000 4040 1500 0 0
								 11000 4050 1000 1 0>;
				strategy_temp_little_cool =	<11000 4050 2500 0 0
								 11000 4050 2000 0 0
								 11000 4190 1650 0 0
								 11000 4190 1500 0 0
								 11000 4200 1000 1 0>;
				strategy_temp_little_cool_high =<11000 4050 3000 0 0
								 11000 4150 2700 0 0
								 11000 4150 2500 0 0
								 11000 4150 2000 0 0
								 11000 4150 1500 0 0
								 11000 4550 1000 1 0>;
				strategy_temp_normal_low =	<11000 4540 4000 0 0
								 11000 4540 3500 0 0
								 11000 4540 3000 0 0
								 11000 4540 2500 0 0
								 11000 4540 2000 0 0
								 11000 4540 1500 0 0
								 11000 4550 1000 1 0>;
				strategy_temp_normal_high =	<11000 4540 4000 0 0
								 11000 4540 3500 0 0
								 11000 4540 3000 0 0
								 11000 4540 2500 0 0
								 11000 4540 2000 0 0
								 11000 4540 1500 0 0
								 11000 4550 1200 1 0>;
				strategy_temp_warm =		<11000 4120 2000 0 0
								 11000 4120 1500 0 0
								 11000 4130 1000 1 0>;
			};
			strategy_soc_range_high { /* 86 ~ 90 */
				strategy_temp_little_cold =	<11000 4070 1100 0 0
								 11000 4080 1000 1 0>;
				strategy_temp_cool =		<11000 4040 1500 0 0
								 11000 4050 1000 1 0>;
				strategy_temp_little_cool =	<11000 4050 2000 0 0
								 11000 4190 1650 0 0
								 11000 4190 1500 0 0
								 11000 4200 1000 1 0>;
				strategy_temp_little_cool_high =<11000 4150 2500 0 0
								 11000 4150 2000 0 0
								 11000 4150 1500 0 0
								 11000 4550 1000 1 0>;
				strategy_temp_normal_low =	<11000 4540 3000 0 0
								 11000 4540 2500 0 0
								 11000 4540 2000 0 0
								 11000 4540 1500 0 0
								 11000 4550 1000 1 0>;
				strategy_temp_normal_high =	<11000 4540 3000 0 0
								 11000 4540 2500 0 0
								 11000 4540 2000 0 0
								 11000 4540 1500 0 0
								 11000 4550 1200 1 0>;
				strategy_temp_warm =		<11000 4120 2000 0 0
								 11000 4120 1500 0 0
								 11000 4130 1000 1 0>;
			};
		};
	};
};
/*for pps config*/

&qupv3_se7_2uart {
	pinctrl-1 = <&qupv3_se7_2uart_sleep_backup>;
	status = "okay";
};

&tlmm {
	qupv3_se7_2uart_sleep_backup:qupv3_se7_2uart_sleep_backup {
		mux {
			pins = "gpio62", "gpio63";
			function = "gpio";
		};

		config {
			pins = "gpio62", "gpio63";
			drive-strength = <2>;
			bias-disable;
			input-enable;
		};
	};
};

&battery_charger {
	compatible = "oplus,hal_sm8350";
	oplus,chg_ops = "plat-pmic";

	qcom,pmic_ftm_vph = "/sys/bus/spmi/drivers/pmic-spmi/0-00/c426000.spmi:pmk8850@0:vadc@9000/iio:device0/in_voltage_pmih010x_vph2_pwr_input";
	qcom,pmic_ftm_vbat = "/sys/bus/spmi/drivers/pmic-spmi/0-00/c426000.spmi:pmk8850@0:vadc@9000/iio:device0/in_voltage_pmih010x_vbat_sns_qbg_input";

	oplus,voocphy_support;
	oplus,batt_num = <1>;
	oplus,otg_scheme = <0>;//0:cid 1:ccdetect_gpio 2:switch
	oplus,bypass_vooc_support;
	oplus,soccp_support;
	oplus,usb_aicl_enhance;
	qcom,otg_boost_src = <0>; /* 0:plat_pmic 1:external */

	oplus_pm8550_charger: oplus,pm8550_charger {
		oplus,ic_type = <OPLUS_CHG_IC_BUCK>;
		oplus,ic_index = <0>;
	};
	oplus_adsp_gauge: oplus,adsp_gauge {
		oplus,ic_type = <OPLUS_CHG_IC_GAUGE>;
		oplus,ic_index = <0>;
	};
	oplus_adsp_pps: oplus,adsp_pps {
		oplus,ic_type = <OPLUS_CHG_IC_PPS>;
		oplus,ic_index = <0>;
	};
};


&pmih010x_gpios {
	usbtemp_l_gpio_default: usbtemp_l_gpio_default {
		pins = "gpio6"; //GPIO 6
		function = "normal"; //normal
		bias-high-impedance; //DISABLE GPIO5 for ADC
		bias-disable;
	};
	usbtemp_r_gpio_default: usbtemp_r_gpio_default {
		pins = "gpio18"; //GPIO 18
		function = "normal"; //normal
		bias-high-impedance; //DISABLE GPIO10 for ADC
		bias-disable;
	};
	subboard_temp_gpio_default: subboard_temp_gpio_default {
		pins = "gpio12"; //GPIO 12
		function = "normal"; //normal
		bias-high-impedance; //DISABLE GPIO6 for ADC
		bias-disable;
	};
	svooc_mos_btb_therm {
		svooc_mos_btb_therm_default: svooc_mos_btb_therm_default {
			pins = "gpio15";
			function = "normal"; //normal
			bias-high-impedance;
			bias-disable;
		};
	};

};

&pmk8850_vadc {
	pinctrl-0 = <&svooc_mos_btb_therm_default>;
	pinctrl-names = "default";

	pmih010x_usb_therm { //for PMIH010X_ADC5_GEN4_AMUX_THM4_USB_THERM_100K_PU
		qcom,adc-tm-type = <0>;
	};

	pmih010x_wls_therm  { //for PMIH010X_ADC5_GEN4_AMUX4_GPIO12_100K_PU
		qcom,adc-tm-type = <0>;
	};

	usb_temp_adc_l {
		reg = <PMIH010X_ADC5_GEN4_AMUX1_GPIO6_100K_PU(1, PMIH010X_SID)>;
		label = "usb_temp_adc_l";
		qcom,pre-scaling = <1 1>;
		qcom,hw-settle-time = <200>;
		qcom,adc5-gen4;
		qcom,scale-fn-type = <OPLUS_ADC_SCALE_HW_CALIB_DEFAULT>;
	};
	usb_temp_adc_r {
		reg = <PMIH010X_ADC5_GEN4_AMUX5_GPIO18_100K_PU(1, PMIH010X_SID)>;
		label = "usb_temp_adc_r";
		qcom,pre-scaling = <1 1>;
		qcom,hw-settle-time = <200>;
		qcom,adc5-gen4;
		qcom,scale-fn-type = <OPLUS_ADC_SCALE_HW_CALIB_DEFAULT>;
	};

	subboard_temp_adc {
		reg = <PMIH010X_ADC5_GEN4_AMUX4_GPIO12_100K_PU(1, PMIH010X_SID)>;
		label = "subboard_temp_adc";
		qcom,pre-scaling = <1 1>;
		qcom,ratiometric;
		qcom,hw-settle-time = <200>;
		qcom,adc5-gen4;
	};
	batt_con_therm_adc {
		reg = <PMIH010X_ADC5_GEN4_AMUX_THM1_BAT_THERM_100K_PU(1, PMIH010X_SID)>;
		label = "batt_con_therm_adc";
		qcom,ratiometric;
		qcom,hw-settle-time = <200>;
		qcom,pre-scaling = <1 1>;
		qcom,adc-tm-type = <0>;
		qcom,adc5-gen4;
	};
	usb_con_therm_adc {
		reg = <PMIH010X_ADC5_GEN4_AMUX_THM4_USB_THERM_100K_PU(1, PMIH010X_SID)>;
		label = "usb_con_therm_adc";
		qcom,ratiometric;
		qcom,hw-settle-time = <200>;
		qcom,pre-scaling = <1 1>;
		qcom,adc-tm-type = <0>;
		qcom,adc5-gen4;
	};

	svooc_mos_btb_therm {
		reg = <PMIH010X_ADC5_GEN4_AMUX2_BAT2_ID_100K_PU(1, PMIH010X_SID)>;
		label = "svooc_mos_btb_therm";
		qcom,ratiometric;
		qcom,hw-settle-time = <200>;
		qcom,pre-scaling = <1 1>;
		qcom,adc-tm-type = <1>;
		qcom,adc5-gen4;
	};

	pmih010x_vph2_pwr {
		reg = <PMIH010X_ADC5_GEN4_VPH2_PWR(1, PMIH010X_SID)>;
		label = "pmih010x_vph2_pwr";
		qcom,pre-scaling = <1 3>;
		qcom,adc5-gen4;
	};
};

&thermal_zones {
	svooc_mos_btb_usr {
		polling-delay-passive = <0>;
		polling-delay = <0>;
		thermal-sensors = <&pmk8850_vadc PMIH010X_ADC5_GEN4_AMUX2_BAT2_ID_100K_PU(1, PMIH010X_SID)>;
		trips {
			active-config0 {
				temperature = <125000>;
				hysteresis = <1000>;
				type = "passive";
			};
		};
	};
};

&battery_charger {
	io-channels	= <&pmk8850_vadc PMIH010X_ADC5_GEN4_AMUX1_GPIO6_100K_PU(1, PMIH010X_SID)>,
					<&pmk8850_vadc PMIH010X_ADC5_GEN4_AMUX5_GPIO18_100K_PU(1, PMIH010X_SID)>,
					<&pmk8850_vadc PMIH010X_ADC5_GEN4_AMUX4_GPIO12_100K_PU(1, PMIH010X_SID)>,
					<&pmk8850_vadc PMIH010X_ADC5_GEN4_AMUX_THM1_BAT_THERM_100K_PU(1, PMIH010X_SID)>,
					<&pmk8850_vadc PMIH010X_ADC5_GEN4_AMUX_THM4_USB_THERM_100K_PU(1, PMIH010X_SID)>,
					<&pmk8850_vadc PMIH010X_ADC5_GEN4_AMUX2_BAT2_ID_100K_PU(1, PMIH010X_SID)>,
					<&pmk8850_vadc PMIH010X_ADC5_GEN4_VPH2_PWR(1, PMIH010X_SID)>,
					<&pmk8850_vadc PMIH010X_ADC5_GEN4_VBAT_SNS_QBG(1, PMIH010X_SID)>,
					<&pmk8850_vadc PMIH010X_ADC5_GEN4_VBAT_SNS_QBG(1, PMIH010X_SID)>;
	io-channel-names = "usb_temp_adc_l", "usb_temp_adc_r", "subboard_temp_adc",
				       "batt_con_therm_adc", "usb_con_therm_adc", "svooc_mos_btb_therm",
				       "vph_pwr", "vbat_sns_qbg", "pmic_vbat_adc";
};

&pmh0110_d_gpios {
	dischg_enable: dischg_enable {
		pins = "gpio5";
		function = "normal";
		bias-disable;
		power-source = <0>;
		output-high;
		qcom,drive-strength = <3>;
	};
	dischg_disable: dischg_disable {
		pins = "gpio5";
		function = "normal";
		bias-disable;
		power-source = <0>;
		output-low;
		qcom,drive-strength = <3>;
	};
};
//#endif OPLUS_FEATURE_CHG_BASIC /*for wired charging config*/

&qupv3_se13_i2c_pins {
	qupv3_se13_i2c_sda_active_oplus: qupv3_se13_i2c_sda_active_oplus {
		mux {
			pins = "gpio64";
			function = "qup3_se0_l0";
		};

		config {
			pins = "gpio64";
			drive-strength = <2>;
			bias-disable;
		};
	};

	qupv3_se13_i2c_scl_active_oplus: qupv3_se13_i2c_scl_active_oplus {
		mux {
			pins = "gpio65";
			function = "qup3_se0_l1";
		};

		config {
			pins = "gpio65";
			drive-strength = <2>;
			bias-disable;
		};
	};

	qupv3_se13_i2c_sleep_oplus: qupv3_se13_i2c_sleep_oplus {
		mux {
			pins = "gpio64", "gpio65";
			function = "gpio";
		};

		config {
			pins = "gpio64", "gpio65";
			drive-strength = <2>;
		};
	};

	qupv3_se13_i2c_pulldown: qupv3_se13_i2c_pulldown {
		mux {
			pins = "gpio64", "gpio65";
			function = "gpio";
		};

		config {
			pins = "gpio64", "gpio65";
			drive-strength = <2>;
			bias-pull-down;
			output-low;
		};
	};

	qupv3_se13_i2c_pullup: qupv3_se13_i2c_pullup {
		mux {
			pins = "gpio64", "gpio65";
			function = "gpio";
		};

		config {
			pins = "gpio64", "gpio65";
			drive-strength = <2>;
			bias-pull-up;
			input-enable;
		};
	};
};

&qupv3_se13_i2c {
	status = "ok";
	qcom,clk-freq-out = <100000>;
	pinctrl-names = "default", "sleep", "pulldown", "pullup";
	pinctrl-0 = <&qupv3_se13_i2c_sda_active_oplus>, <&qupv3_se13_i2c_scl_active_oplus>;
	pinctrl-1 = <&qupv3_se13_i2c_sleep_oplus>;
	pinctrl-2 = <&qupv3_se13_i2c_pulldown>;
	pinctrl-3 = <&qupv3_se13_i2c_pullup>;

	oplus_ext_gauge: bq27541-battery@55 {
		status = "okay";
		compatible = "oplus,bq27541-battery";
		reg = <0x55>;
		qcom,modify-soc-calibration;
		oplus,batt_num = <1>;
		oplus,support_extern_cmd;
		oplus,calib_info_save_support;
		oplus,batt_nfg8011b;

		oplus,ic_type = <OPLUS_CHG_IC_GAUGE>;
		oplus,ic_index = <0>;
	};
};

&tlmm {
	charging_inter_active: charging_inter_active {
		mux {
			pins = "gpio170";
			function = "gpio";
		};
		config {
			pins = "gpio170";
			bias-pull-up;
			drive-strength = <2>;
			input-enable;
		};
	};

	charging_inter_sleep: charging_inter_sleep {
		mux {
			pins = "gpio170";
			function = "gpio";
		};
		config {
			pins = "gpio170";
			bias-pull-up;
			drive-strength = <2>;
			input-enable;
		};
	};

	slave_charging_inter_active: slave_charging_inter_active {
		mux {
			pins = "gpio11";
			function = "gpio";
		};
		config {
			pins = "gpio11";
			bias-pull-up;
			drive-strength = <2>;
			input-enable;
		};
	};

	slave_charging_inter_sleep: slave_charging_inter_sleep {
		mux {
			pins = "gpio11";
			function = "gpio";
		};
		config {
			pins = "gpio11";
			bias-pull-up;
			drive-strength = <2>;
			input-enable;
		};
	};
};

&qupv3_hub_i2c1 {
	status = "okay";
	qcom,clk-freq-out = <400000>;

	oplus_sc8547_slave: sc8547-charger-slave@6A{
		status = "okay";
		compatible = "oplus,sc8547d";
		reg = <0x6A>;
		ocp_reg = <0xe>;
		ovp_reg = <0x36>;
		vbus_ovp_reg = /bits/ 8 <0x5A>;
		oplus,use_slave_cp;

		oplus_spec,irq_gpio = <&tlmm 11 0x00>;

		pinctrl-names = "charging_inter_active", "charging_inter_sleep";
		pinctrl-0 = <&slave_charging_inter_active>;
		pinctrl-1 = <&slave_charging_inter_sleep>;

		oplus_sc8547_slave_cp: oplus,sc8547_slave_cp {
			oplus,ic_type = <OPLUS_CHG_IC_CP>;
			oplus,ic_index = <1>;
		};
	};
};

&qupv3_hub_i2c0 {
	status = "okay";
	qcom,clk-freq-out = <400000>;

	oplus_sc8547d: oplus,sc8547d@6A {
		status = "okay";
		compatible = "oplus,sc8547d";
		reg = <0x6A>;
		oplus,use_vooc_phy;
		oplus,use_ufcs_phy;

		oplus_spec,irq_gpio = <&tlmm 170 0x00>;

		pinctrl-names = "charging_inter_active", "charging_inter_sleep";
		pinctrl-0 = <&charging_inter_active>;
		pinctrl-1 = <&charging_inter_sleep>;

		oplus,ic_type = <OPLUS_CHG_IC_VPHY>;
		oplus,ic_index = <0>;
		oplus,vooc-version = <VOOC_VERSION_5_0>;

		oplus_spec,vooc_bad_volt = <3450 3400 3350 3300>;
		oplus_spec,vooc_bad_volt_suspend = <3450 3400 3350 3300>;
		oplus_spec,vooc_bad_volt_check_head_mask = /bits/ 8 <0x3>; /* VOOC 2.0/VOOC3.0 */
		oplus_spec,ap_control_allow;
		oplus,vbus_adjust_new_method;

		oplus_spec,external_gauge_support;
		oplus_spec,voocphy_current_default = <91>;

		oplus_spec,vooc_little_cold_full_voltage = <0>;
		oplus_spec,vooc_cool_full_voltage = <4050>;
		oplus_spec,vooc_warm_full_voltage = <4130>;
		oplus_spec,vooc_1time_full_voltage = <4560>;
		oplus_spec,vooc_ntime_full_voltage = <4550>;
		oplus_spec,full_voltage = < /* vol_1time vol_ntime */
					4090 4080 /* 0 ~ 5 */
					4060 4050 /* 5 ~ 12 */
					4210 4200 /* 12 ~ 16 */
					4560 4550 /* 16 ~ 20 */
					4560 4550 /* 20 ~ 35 */
					4560 4550 /* 35 ~ 44 */
					4140 4130 /* 44 ~ 51 */
					>;

		ocp_reg = <0xf>;
		ovp_reg = <0x36>;
		vbus_ovp_reg = /bits/ 8 <0x5A>;
		oplus_spec,voocphy_dual_cp_support;
		oplus_spec,slave_cp_enable_thr = <1900>;
		oplus_spec,slave_cp_disable_thr_high = <1600>;
		oplus_spec,impedance_calculation_newmethod;
		oplus_spec,svooc_circuit_r_l = <0xa>;
		oplus_spec,svooc_circuit_r_h = <0x1>;

		oplus_spec,vooc_multistep_initial_batt_temp = <1000>;
		oplus_spec,vooc_little_cool_temp = <160>;
		oplus_spec,vooc_little_cool_high_temp = <210>;
		oplus_spec,vooc_cool_temp = <120>;
		oplus_spec,vooc_little_cold_temp = <50>;
		oplus_spec,vooc_normal_low_temp = <350>;
		oplus_spec,vooc_normal_to_little_cool_current = <100>;
		oplus_spec,vooc_over_high_temp = <510>;
		oplus_spec,vooc_low_temp = <50>;
		oplus_spec,vooc_high_temp = <500>;
		oplus_spec,vooc_low_soc = <0>;
		oplus_spec,vooc_high_soc = <90>;
		oplus_spec,vooc_normal_high_temp = <440>;
		oplus_spec,vooc_warm_vol_thr = <4000>;
		oplus_spec,vooc_warm_soc_thr = <55>;
		oplus_spec,vooc_full_recheck_temp = <210>;

		oplus_spec,fastchg_timeout_time_init = <183080>;
		oplus_spec,voocphy_ibat_over_current = <19600>;
		oplus_spec,voocphy_cp_max_ibus = <5300>;

		oplus_spec,voocphy_req_freq = <1785600 2438400>;
		oplus_spec,voocphy_freq_mincore = <1785600>;
		oplus_spec,voocphy_freq_midcore = <2438400>;
		oplus_spec,voocphy_freq_maxcore = <2438400>;
		oplus_spec,voocphy_current_change_timeout = <100>;
		oplus_spec,copycat_vooc_support;

		oplus_spec,soc_range = <0 20 35 55 75 85 90>;

		svooc_batt_sys_curve = <1 0 1 1 0 1 1	// 9100mA
					0 0 0 0 0 0 1	// 3414mV
					0 0 1 1 0 1 0	// 2600mA
					1 1 1 1 1 1 0	// 4664mV
					0 0 0 1 0 1 1	// 1100mA
					1 1 1 1 1 1 0>;	// 4664mV

		vooc_batt_sys_curve =  <0 1 1 1 1 0 0	// 6000mA
					0 0 0 0 0 0 1	// 3414mV
					0 0 1 1 0 1 0	// 2600mA
					1 1 1 1 1 1 0	// 4664mV
					0 0 0 1 0 1 1	// 1100mA
					1 1 1 1 1 1 0>;	// 4664mV

		oplus,pcc_strategy_name = "pcc_strategy_v2";
		svooc_pcc_strategy {};

		svooc_lcf_strategy {
			oplus,temp_type = <OPLUS_STRATEGY_USE_SHELL_TEMP>;
			oplus,temp_range = <0 50 120 160 210 380 440>;

			strategy_temp_range_curves {
				strategy_temp_range_t0 =	<356  4530 0
								 331  4520 0
								 306  4510 0
								 281  4500 0
								 256  4490 1>;
				strategy_temp_range_t1 =	<850  4550 0
								 800  4545 0
								 750  4530 0
								 650  4520 0
								 550  4510 1>;
				strategy_temp_range_t2 =	<1050 4550 0
								 1000 4545 0
								 900  4530 0
								 800  4520 0
								 650  4510 1>;
				strategy_temp_range_t3 =	<1250 4550 0
								 1200 4545 0
								 1100 4530 0
								 1000 4520 0
								 850  4510 1>;
				strategy_temp_range_t4 =	<1450 4550 0
								 1400 4545 0
								 1300 4530 0
								 1200 4520 0
								 1050 4510 1>;
				strategy_temp_range_t5 =	<2100 4546 0
								 1900 4543 0
								 1600 4535 0
								 1300 4525 0
								 1000 4515 1>;
			};
		};

		svooc_charge_strategy {
			strategy_soc_0_to_50 { /* 0 ~ 20 */
				strategy_temp_little_cold =	<4070 11 0 0 0
								 4080 10 1 0 0>;
				strategy_temp_cool =		<4040 16 0 0 0
								 4040 15 0 0 0
								 4050 10 1 0 0>;
				strategy_temp_little_cool =	<4050 27 0 0 0
								 4050 25 0 0 0
								 4050 20 0 0 0
								 4190 16 0 0 0
								 4190 15 0 0 0
								 4200 10 1 0 0>;
				strategy_temp_little_cool_high = <4050 40 0 0 0
								 4050 35 0 0 0
								 4050 30 0 0 0
								 4150 27 0 0 0
								 4150 25 0 0 0
								 4150 20 0 0 0
								 4150 15 0 0 0
								 4550 10 1 0 0>;
				strategy_temp_normal_low =	<4030 91 0 120 0
								 4030 75 0 0 0
								 4060 74 0 540 0
								 4060 70 0 0 0
								 4060 60 0 0 0
								 4160 57 0 1020 0
								 4160 55 0 0 0
								 4380 50 0 0 0
								 4380 45 0 0 0
								 4510 44 0 0 0
								 4540 42 0 0 0
								 4540 40 0 0 0
								 4540 35 0 0 0
								 4540 30 0 0 0
								 4540 25 0 0 0
								 4540 20 0 0 0
								 4540 15 0 0 0
								 4550 10 1 0 0>;
				strategy_temp_normal_high =	<4030 91 0 120 0
								 4030 75 0 0 0
								 4060 74 0 540 0
								 4060 70 0 0 0
								 4060 60 0 0 0
								 4160 57 0 1020 0
								 4160 55 0 0 0
								 4380 50 0 0 0
								 4380 45 0 0 0
								 4510 44 0 0 0
								 4540 42 0 0 0
								 4540 40 0 0 0
								 4540 35 0 0 0
								 4540 30 0 0 0
								 4540 25 0 0 0
								 4540 20 0 0 0
								 4540 15 0 0 0
								 4550 12 1 0 0>;
				strategy_temp_warm =		<4120 20 0 0 0
								 4120 15 0 0 0
								 4130 10 1 0 0>;
			};

			strategy_soc_0_to_50_mid { /* 21 ~ 35 */
				strategy_temp_little_cold =	<4070 11 0 0 0
								 4080 10 1 0 0>;
				strategy_temp_cool =		<4040 16 0 0 0
								 4040 15 0 0 0
								 4050 10 1 0 0>;
				strategy_temp_little_cool =	<4050 27 0 0 0
								 4050 25 0 0 0
								 4050 20 0 0 0
								 4190 16 0 0 0
								 4190 15 0 0 0
								 4200 10 1 0 0>;
				strategy_temp_little_cool_high = <4050 40 0 0 0
								 4050 35 0 0 0
								 4050 30 0 0 0
								 4150 27 0 0 0
								 4150 25 0 0 0
								 4150 20 0 0 0
								 4150 15 0 0 0
								 4550 10 1 0 0>;
				strategy_temp_normal_low =	<4030 91 0 120 0
								 4030 75 0 0 0
								 4060 74 0 540 0
								 4060 70 0 0 0
								 4060 60 0 0 0
								 4160 57 0 1020 0
								 4160 55 0 0 0
								 4380 50 0 0 0
								 4380 45 0 0 0
								 4510 44 0 0 0
								 4540 42 0 0 0
								 4540 40 0 0 0
								 4540 35 0 0 0
								 4540 30 0 0 0
								 4540 25 0 0 0
								 4540 20 0 0 0
								 4540 15 0 0 0
								 4550 10 1 0 0>;
				strategy_temp_normal_high =	<4030 91 0 120 0
								 4030 75 0 0 0
								 4060 74 0 540 0
								 4060 70 0 0 0
								 4060 60 0 0 0
								 4160 57 0 1020 0
								 4160 55 0 0 0
								 4380 50 0 0 0
								 4380 45 0 0 0
								 4510 44 0 0 0
								 4540 42 0 0 0
								 4540 40 0 0 0
								 4540 35 0 0 0
								 4540 30 0 0 0
								 4540 25 0 0 0
								 4540 20 0 0 0
								 4540 15 0 0 0
								 4550 12 1 0 0>;
				strategy_temp_warm =		<4120 20 0 0 0
								 4120 15 0 0 0
								 4130 10 1 0 0>;
			};

			strategy_soc_0_to_50_high { /* 36 ~ 55 */
				strategy_temp_little_cold =	<4070 11 0 0 0
								 4080 10 1 0 0>;
				strategy_temp_cool =		<4040 16 0 0 0
								 4040 15 0 0 0
								 4050 10 1 0 0>;
				strategy_temp_little_cool =	<4050 27 0 0 0
								 4050 25 0 0 0
								 4050 20 0 0 0
								 4190 16 0 0 0
								 4190 15 0 0 0
								 4200 10 1 0 0>;
				strategy_temp_little_cool_high = <4050 40 0 0 0
								 4050 35 0 0 0
								 4050 30 0 0 0
								 4150 27 0 0 0
								 4150 25 0 0 0
								 4150 20 0 0 0
								 4150 15 0 0 0
								 4550 10 1 0 0>;
				strategy_temp_normal_low =	<4030 91 0 120 0
								 4030 75 0 0 0
								 4060 74 0 540 0
								 4060 70 0 0 0
								 4060 60 0 0 0
								 4160 57 0 1020 0
								 4160 55 0 0 0
								 4380 50 0 0 0
								 4380 45 0 0 0
								 4510 44 0 0 0
								 4540 42 0 0 0
								 4540 40 0 0 0
								 4540 35 0 0 0
								 4540 30 0 0 0
								 4540 25 0 0 0
								 4540 20 0 0 0
								 4540 15 0 0 0
								 4550 10 1 0 0>;
				strategy_temp_normal_high =	<4030 91 0 120 0
								 4030 75 0 0 0
								 4060 74 0 540 0
								 4060 70 0 0 0
								 4060 60 0 0 0
								 4160 57 0 1020 0
								 4160 55 0 0 0
								 4380 50 0 0 0
								 4380 45 0 0 0
								 4510 44 0 0 0
								 4540 42 0 0 0
								 4540 40 0 0 0
								 4540 35 0 0 0
								 4540 30 0 0 0
								 4540 25 0 0 0
								 4540 20 0 0 0
								 4540 15 0 0 0
								 4550 12 1 0 0>;
				strategy_temp_warm =		<4120 20 0 0 0
								 4120 15 0 0 0
								 4130 10 1 0 0>;
			};

			strategy_soc_50_to_75 { /* 56 ~ 75 */
				strategy_temp_little_cold =	<4070 11 0 0 0
								 4080 10 1 0 0>;
				strategy_temp_cool =		<4040 16 0 0 0
								 4040 15 0 0 0
								 4050 10 1 0 0>;
				strategy_temp_little_cool =	<4050 27 0 0 0
								 4050 25 0 0 0
								 4050 20 0 0 0
								 4190 16 0 0 0
								 4190 15 0 0 0
								 4200 10 1 0 0>;
				strategy_temp_little_cool_high = <4050 40 0 0 0
								 4050 35 0 0 0
								 4050 30 0 0 0
								 4150 27 0 0 0
								 4150 25 0 0 0
								 4150 20 0 0 0
								 4150 15 0 0 0
								 4550 10 1 0 0>;
				strategy_temp_normal_low =	<4060 60 0 0 0
								 4160 57 0 1020 0
								 4160 55 0 0 0
								 4380 50 0 0 0
								 4380 45 0 0 0
								 4510 44 0 0 0
								 4540 42 0 0 0
								 4540 40 0 0 0
								 4540 35 0 0 0
								 4540 30 0 0 0
								 4540 25 0 0 0
								 4540 20 0 0 0
								 4540 15 0 0 0
								 4550 10 1 0 0>;
				strategy_temp_normal_high =	<4060 70 0 0 0
								 4060 60 0 0 0
								 4160 57 0 1020 0
								 4160 55 0 0 0
								 4380 50 0 0 0
								 4380 45 0 0 0
								 4510 44 0 0 0
								 4540 42 0 0 0
								 4540 40 0 0 0
								 4540 35 0 0 0
								 4540 30 0 0 0
								 4540 25 0 0 0
								 4540 20 0 0 0
								 4540 15 0 0 0
								 4550 12 1 0 0>;
				strategy_temp_warm =		<4120 20 0 0 0
								 4120 15 0 0 0
								 4130 10 1 0 0>;
			};

			strategy_soc_75_to_85 { /* 76 ~ 85 */
				strategy_temp_little_cold =	<4070 11 0 0 0
								 4080 10 1 0 0>;
				strategy_temp_cool =		<4040 16 0 0 0
								 4040 15 0 0 0
								 4050 10 1 0 0>;
				strategy_temp_little_cool =	<4050 27 0 0 0
								 4050 25 0 0 0
								 4050 20 0 0 0
								 4190 16 0 0 0
								 4190 15 0 0 0
								 4200 10 1 0 0>;
				strategy_temp_little_cool_high = <4050 40 0 0 0
								 4050 35 0 0 0
								 4050 30 0 0 0
								 4150 27 0 0 0
								 4150 25 0 0 0
								 4150 20 0 0 0
								 4150 15 0 0 0
								 4550 10 1 0 0>;
				strategy_temp_normal_low =	<4380 50 0 0 0
								 4380 45 0 0 0
								 4510 44 0 0 0
								 4540 42 0 0 0
								 4540 40 0 0 0
								 4540 35 0 0 0
								 4540 30 0 0 0
								 4540 25 0 0 0
								 4540 20 0 0 0
								 4540 15 0 0 0
								 4550 10 1 0 0>;
				strategy_temp_normal_high =	<4060 60 0 0 0
								 4160 57 0 1020 0
								 4160 55 0 0 0
								 4380 50 0 0 0
								 4380 45 0 0 0
								 4510 44 0 0 0
								 4540 42 0 0 0
								 4540 40 0 0 0
								 4540 35 0 0 0
								 4540 30 0 0 0
								 4540 25 0 0 0
								 4540 20 0 0 0
								 4540 15 0 0 0
								 4550 12 1 0 0>;
				strategy_temp_warm =		<4120 20 0 0 0
								 4120 15 0 0 0
								 4130 10 1 0 0>;
			};

			strategy_soc_85_to_90 { /* 86 ~ 90 */
				strategy_temp_little_cold =	<4070 11 0 0 0
								 4080 10 1 0 0>;
				strategy_temp_cool =		<4040 15 0 0 0
								 4050 10 1 0 0>;
				strategy_temp_little_cool =	<4050 20 0 0 0
								 4190 16 0 0 0
								 4190 15 0 0 0
								 4200 10 1 0 0>;
				strategy_temp_little_cool_high = <4050 30 0 0 0
								 4150 27 0 0 0
								 4150 25 0 0 0
								 4150 20 0 0 0
								 4150 15 0 0 0
								 4550 10 1 0 0>;
				strategy_temp_normal_low =	<4540 40 0 0 0
								 4540 35 0 0 0
								 4540 30 0 0 0
								 4540 25 0 0 0
								 4540 20 0 0 0
								 4540 15 0 0 0
								 4550 10 1 0 0>;
				strategy_temp_normal_high =	<4380 50 0 0 0
								 4380 45 0 0 0
								 4510 44 0 0 0
								 4540 42 0 0 0
								 4540 40 0 0 0
								 4540 35 0 0 0
								 4540 30 0 0 0
								 4540 25 0 0 0
								 4540 20 0 0 0
								 4540 15 0 0 0
								 4550 12 1 0 0>;
				strategy_temp_warm =		<4120 20 0 0 0
								 4120 15 0 0 0
								 4130 10 1 0 0>;
			};
		};

		vooc_charge_strategy {
			strategy_soc_0_to_50 { /* 0 ~ 20 */
				strategy_temp_little_cold =	<4070 22 0 0 0
								 4080 20 1 0 0>;
				strategy_temp_cool =		<4040 32 0 0 0
								 4040 30 0 0 0
								 4050 20 1 0 0>;
				strategy_temp_little_cool =	<4050 54 0 0 0
								 4050 50 0 0 0
								 4050 40 0 0 0
								 4190 32 0 0 0
								 4190 30 0 0 0
								 4200 20 1 0 0>;
				strategy_temp_little_cool_high =<4050 60 0 0 0
								 4150 54 0 0 0
								 4150 50 0 0 0
								 4150 40 0 0 0
								 4150 30 0 0 0
								 4550 20 1 0 0>;
				strategy_temp_normal_low =	<4540 60 0 0 0
								 4540 50 0 0 0
								 4540 40 0 0 0
								 4540 30 0 0 0
								 4550 20 1 0 0>;
				strategy_temp_normal_high =	<4540 60 0 0 0
								 4540 50 0 0 0
								 4540 40 0 0 0
								 4540 30 0 0 0
								 4550 24 1 0 0>;
				strategy_temp_warm =		<4120 40 0 0 0
								 4120 30 0 0 0
								 4130 20 1 0 0>;
			};

			strategy_soc_0_to_50_mid { /* 21 ~ 35 */
				strategy_temp_little_cold =	<4070 22 0 0 0
								 4080 20 1 0 0>;
				strategy_temp_cool =		<4040 32 0 0 0
								 4040 30 0 0 0
								 4050 20 1 0 0>;
				strategy_temp_little_cool =	<4050 54 0 0 0
								 4050 50 0 0 0
								 4050 40 0 0 0
								 4190 32 0 0 0
								 4190 30 0 0 0
								 4200 20 1 0 0>;
				strategy_temp_little_cool_high =<4050 60 0 0 0
								 4150 54 0 0 0
								 4150 50 0 0 0
								 4150 40 0 0 0
								 4150 30 0 0 0
								 4550 20 1 0 0>;
				strategy_temp_normal_low =	<4540 60 0 0 0
								 4540 50 0 0 0
								 4540 40 0 0 0
								 4540 30 0 0 0
								 4550 20 1 0 0>;
				strategy_temp_normal_high =	<4540 60 0 0 0
								 4540 50 0 0 0
								 4540 40 0 0 0
								 4540 30 0 0 0
								 4550 24 1 0 0>;
				strategy_temp_warm =		<4120 40 0 0 0
								 4120 30 0 0 0
								 4130 20 1 0 0>;
			};

			strategy_soc_0_to_50_high { /* 36 ~ 55 */
				strategy_temp_little_cold =	<4070 22 0 0 0
								 4080 20 1 0 0>;
				strategy_temp_cool =		<4040 32 0 0 0
								 4040 30 0 0 0
								 4050 20 1 0 0>;
				strategy_temp_little_cool =	<4050 54 0 0 0
								 4050 50 0 0 0
								 4050 40 0 0 0
								 4190 32 0 0 0
								 4190 30 0 0 0
								 4200 20 1 0 0>;
				strategy_temp_little_cool_high =<4050 60 0 0 0
								 4150 54 0 0 0
								 4150 50 0 0 0
								 4150 40 0 0 0
								 4150 30 0 0 0
								 4550 20 1 0 0>;
				strategy_temp_normal_low =	<4540 60 0 0 0
								 4540 50 0 0 0
								 4540 40 0 0 0
								 4540 30 0 0 0
								 4550 20 1 0 0>;
				strategy_temp_normal_high =	<4540 60 0 0 0
								 4540 50 0 0 0
								 4540 40 0 0 0
								 4540 30 0 0 0
								 4550 24 1 0 0>;
				strategy_temp_warm =		<4120 40 0 0 0
								 4120 30 0 0 0
								 4130 20 1 0 0>;
			};

			strategy_soc_50_to_75 { /* 56 ~ 75 */
				strategy_temp_little_cold =	<4070 22 0 0 0
								 4080 20 1 0 0>;
				strategy_temp_cool =		<4040 32 0 0 0
								 4040 30 0 0 0
								 4050 20 1 0 0>;
				strategy_temp_little_cool =	<4050 54 0 0 0
								 4050 50 0 0 0
								 4050 40 0 0 0
								 4190 32 0 0 0
								 4190 30 0 0 0
								 4200 20 1 0 0>;
				strategy_temp_little_cool_high =<4050 60 0 0 0
								 4150 54 0 0 0
								 4150 50 0 0 0
								 4150 40 0 0 0
								 4150 30 0 0 0
								 4550 20 1 0 0>;
				strategy_temp_normal_low =	<4540 60 0 0 0
								 4540 50 0 0 0
								 4540 40 0 0 0
								 4540 30 0 0 0
								 4550 20 1 0 0>;
				strategy_temp_normal_high =	<4540 60 0 0 0
								 4540 50 0 0 0
								 4540 40 0 0 0
								 4540 30 0 0 0
								 4550 24 1 0 0>;
				strategy_temp_warm =		<4120 40 0 0 0
								 4120 30 0 0 0
								 4130 20 1 0 0>;
			};

			strategy_soc_75_to_85 { /* 76 ~ 85 */
				strategy_temp_little_cold =	<4070 22 0 0 0
								 4080 20 1 0 0>;
				strategy_temp_cool =		<4040 32 0 0 0
								 4040 30 0 0 0
								 4050 20 1 0 0>;
				strategy_temp_little_cool =	<4050 54 0 0 0
								 4050 50 0 0 0
								 4050 40 0 0 0
								 4190 32 0 0 0
								 4190 30 0 0 0
								 4200 20 1 0 0>;
				strategy_temp_little_cool_high =<4050 60 0 0 0
								 4150 54 0 0 0
								 4150 50 0 0 0
								 4150 40 0 0 0
								 4150 30 0 0 0
								 4550 20 1 0 0>;
				strategy_temp_normal_low =	<4540 60 0 0 0
								 4540 50 0 0 0
								 4540 40 0 0 0
								 4540 30 0 0 0
								 4550 20 1 0 0>;
				strategy_temp_normal_high =	<4540 60 0 0 0
								 4540 50 0 0 0
								 4540 40 0 0 0
								 4540 30 0 0 0
								 4550 24 1 0 0>;
				strategy_temp_warm =		<4120 40 0 0 0
								 4120 30 0 0 0
								 4130 20 1 0 0>;
			};

			strategy_soc_85_to_90 { /* 86 ~ 90 */
				strategy_temp_little_cold =	<4070 22 0 0 0
								 4080 20 1 0 0>;
				strategy_temp_cool =		<4040 30 0 0 0
								 4050 20 1 0 0>;
				strategy_temp_little_cool =	<4050 40 0 0 0
								 4190 32 0 0 0
								 4190 30 0 0 0
								 4200 20 1 0 0>;
				strategy_temp_little_cool_high =<4050 60 0 0 0
								 4150 54 0 0 0
								 4150 50 0 0 0
								 4150 40 0 0 0
								 4150 30 0 0 0
								 4550 20 1 0 0>;
				strategy_temp_normal_low =	<4540 60 0 0 0
								 4540 50 0 0 0
								 4540 40 0 0 0
								 4540 30 0 0 0
								 4550 20 1 0 0>;
				strategy_temp_normal_high =	<4540 60 0 0 0
								 4540 50 0 0 0
								 4540 40 0 0 0
								 4540 30 0 0 0
								 4550 24 1 0 0>;
				strategy_temp_warm =		<4120 40 0 0 0
								 4120 30 0 0 0
								 4130 20 1 0 0>;
			};
		};

		oplus_sc8547_cp: oplus,sc8547_cp {
			oplus,ic_type = <OPLUS_CHG_IC_CP>;
			oplus,ic_index = <0>;
			oplus,ic_func_group = <&sc8547_cp_groups>;
		};
	};
};

//#ifdef OPLUS_FEATURE_CHG_BASIC /* BSP.CHG.Basic, 2023/04/19, sjc Add for wls charging */
//for wls charging config
&battery_charger {
	oplus,wls_boost_vol_start_mv = <7000>;
	oplus,wls_boost_vol_max_mv = <7000>;
	oplus,wls_boost_src = <1>;/*0:pmic otg, 1:pmic wls */
};

&oplus_mms_wired {
	oplus,support_wlsotg_non_coexistence;
};

&soc {
	oplus_chg_wls: oplus,chg_wls {
		status = "ok";
		compatible = "oplus,chg_wls";

		oplus,rx_ic = <&oplus_virtual_rx>;
		oplus,nor_ic = <&oplus_virtual_buck>;
		oplus,fast_ic = <&oplus_wls_virtual_cp>;

		oplus,support_fastchg;
		oplus,support_epp_plus;
		oplus,support_wls_chg_bcc;
		oplus,support_acdrv_no_ext_boost;
		oplus,support_no_hw_interlock;

		oplus,max-voltage-mv = <4550>;
		oplus,fastchg_curr_max_ma = <5000>;
		oplus,verity_curr_max_ma = <5000>;
		oplus,wls-fast-chg-call-on-curr-ma = <600>;
		oplus,wls-fast-chg-camera-on-curr-ma = <600>;
		oplus,wls_power_mw = <50000>;
		oplus,wls_phone_id = <0x21>;
		oplus,wls-bcc-fcc-to-icl-factor = <2>;
		oplus,normal_high_batt_temp = <210>;
		oplus,little_warm_batt_temp = <350>;
		oplus,wls_boost_curr_limit_ma = <1500>;
		oplus,rx_protocol_version = <30>;
		oplus,rx_coil = <48>;
		oplus,vbridge_ratio = <40>;
		oplus,magcvr_vbridge_ratio = <40>;
		oplus,non_mag_power_mw = <20000>;
		/*
		 * | temp_min | temp_max | target_curr_ma(mA) |
		 *
		 * temp_min: Switch to the previous level when the temperature is lower
		 *           than this value. If it is 0, do not switch.
		 * temp_max: Switch to the next level when the temperature is greater
		 *           than this value
		 */
		oplus,epp_plus-skin-step = <0 360 1700
					    350 380 1700
					    360 390 1700
					    370 410 1700>;
		oplus,epp-skin-step = <0 390 1500
				       360 400 1500>;
		oplus,bpp-skin-step = <0 390 750
				       370 400 750>;
		oplus,epp_plus-led-on-skin-step = <0 390 1700
						   380 500 1700>;
		oplus,epp-led-on-skin-step = <0 390 1500
					      380 500 1500>;

		/*
		 * | cool_temp | heat_temp | curr_data | heat_next_index | cool_next_index |
		 */
		oplus,wls-fast-chg-led-off-strategy-data = <0 410 5000 1 0
							    390 450 2400 1 0>;
		oplus,wls-fast-chg-led-on-strategy-data = <0 340 5000 1 0
							   330 360 2000 2 0
							   350 380 1600 3 1
							   370 400 1200 3 2>;

		oplus,iclmax-ma = <300 750 750 750 750 750 750 750 750 300    /*wls-bpp(mA)*/
				   600 800 1500 1500 1500 1500 1500 1500 800 600    /*wls-epp(mA)*/
				   600 800 1700 1700 1700 1700 1700 1700 800 600    /*wls-epp-plus(mA)*/
				   600 750 1800 1800 1800 1800 1800 1800 750 600    /*wls-airvooc(mA)*/
				   600 800 2000 2500 5000 5000 5000 5000 800 600>;  /*wls-airsvooc(mA)*/
		oplus,iclmax-batt-high-ma = <300 400 750 750 750 750 750 750 750 300    /*wls-bpp(mA)*/
					     600 500 800 1500 1500 1500 1500 1500 800 600    /*wls-epp(mA)*/
					     600 500 800 1700 1700 1700 1700 1700 800 600    /*wls-epp-plus(mA)*/
					     600 400 750 1800 1800 1800 1800 1800 750 600    /*wls-airvooc(mA)*/
					     600 400 2000 2500 5000 5000 5000 5000 800 600>;  /*wls-airsvooc(mA)*/

		/*
		 * | temp_min | temp_max | target_curr_ma | vol_max_mv | need_wait |
		 * temp_min/temp_max: not use here
		 * target_curr_ma: wls icl when vbat < vol_max_mv
		 * vol_max_mv: the last value is always 5000mV(must be greater than the max-vbat)
		 * need_wait: not use here
		 * if there is non_ffc_strategy, use the parameter in non_ffc_strategy
		 */
		non-ffc-bpp =		<0 0 750 5000 0>;
		non-ffc-epp =		<0 0 1500 4385 0
					 0 0 800 5000 0>;
		non-ffc-epp-plus =	<0 0 1700 4380 0
					 0 0 1500 4385 0
					 0 0 800 5000 0>;
		non-ffc-airvooc =	<0 0 2000 4375 0
					 0 0 800 5000 0>;
		non-ffc-airsvooc =	<0 0 2000 4425 0
					 0 0 800 5000 0>;
		/*
		 * | temp_min | temp_max | target_curr_ma | vol_max_mv | need_wait |
		 * temp_min: Switch to the previous level when the temperature is lower
		 *           than this value. If it is 0, do not switch.
		 * temp_max: Switch to the next level when the temperature is higher
		 *           than this value
		 * target_curr_ma: wls icl when vbat > vol_max_mv
		 * vol_max_mv: Maximum battery voltage.
		 * need_wait: not use here
		 */
		cv-bpp = 	<(-100) 350 400 4465 0
				350 450 400 4450 0
				450 530 400 4100 0>;
		cv-epp =	<(-100) 0 400 4465 0
				0 350 600 4465 0
				350 450 600 4450 0
				450 530 600 4100 0>;
		cv-epp-plus =	<(-100) 0 400 4465 0
				0 350 600 4465 0
				350 450 600 4450 0
				450 530 600 4100 0>;
		cv-airvooc =	<(-100) 0 400 4465 0
				0 350 600 4465 0
				350 450 600 4450 0
				450 530 600 4100 0>;
		cv-airsvooc =	<(-100) 0 400 4465 0
				0 350 600 4465 0
				350 450 600 4450 0
				450 530 600 4100 0>;

		cv-bpp-high-batt = 	<(-100) 0 250 4465 0
				0 350 400 4465 0
				350 450 400 4450 0
				450 530 400 4100 0>;
		cv-epp-high-batt =	<(-100) 0 200 4465 0
				0 50 400 4465 0
				50 350 600 4465 0
				350 450 600 4450 0
				450 530 600 4100 0>;
		cv-epp-plus-high-batt =	<(-100) 0 200 4465 0
				0 50 400 4465 0
				50 350 600 4465 0
				350 450 600 4450 0
				450 530 600 4100 0>;
		cv-airvooc-high-batt =	<(-100) 0 200 4465 0
				0 50 400 4465 0
				50 350 600 4465 0
				350 450 600 4450 0
				450 530 600 4100 0>;
		cv-airsvooc-high-batt =	<(-100) 0 200 4465 0
				0 50 400 4465 0
				50 350 600 4465 0
				350 450 600 4450 0
				450 530 600 4100 0>;

		oplus,cool-down-12v-thr = <2>;//switch to 12V level
		cool-down-bpp = <0 750 750 750 750 750 750>;
		cool-down-epp = <0 800 800 1500 1500 1500 1500>;
		cool-down-epp-plus = <0 800 800 1500 1500 1500 1700>;
		cool-down-airvooc = <0 800 800 1800 1800 1800 1800>;
		cool-down-airsvooc = <0 800 2000 1500 1500 2000 2500 2500 2500 2500 2500 2500 2500>;

		/*
		 * | bcc_stop_curr |
		 * The three parameters of each array
		 * correspond to three temperature intervals: 0-5; 5-12; 12-44
		 */
		bcc_stop_curr_0_to_30 = <2000 2000 2000 2000 2000 2000>;
		bcc_stop_curr_0_to_30_high = <2000 2000 2000 2000 2000 2000>;
		bcc_stop_curr_30_to_70 = <2000 2000 2000 2000 2000 2000>;
		bcc_stop_curr_30_to_70_high = <2000 2000 2000 2000 2000 2000>;
		bcc_stop_curr_70_to_90 = <2000 2000 2000 2000 2000 2000>;
		bcc_stop_curr_70_to_90_high = <2000 2000 2000 2000 2000 2000>;
		/*
		 * | curr_ma | fallback_step | switch_to_bpp
		 * curr_ma: wls icl in this step
		 * fallback_step: 0: don't fallback when CEP is OK
		 *                1/2...: fallback to 1st/2nd step when CEP is OK
		 * switch_to_bpp: reach the final step, switch to bpp when CEP is not OK
		 */
		skewing-epp =		<1500 0 0
					 1100 0 0
					 800 1 0>;
		skewing-epp-plus =	<1700 0 0
					 1500 0 0
					 1100 2 0
					 800 3 0>;//fallback to 800(2nd step) when CEP is OK at this step
		skewing-airvooc =	<1800 0 0
					 750 0 0>;

		/* fod parameter*/
		/*
		 * oplus,fastchg-match-q: | wls_base(dock) id | q value | f value
		 * oplus,fod-parm-array-row-len: dock id len(1) + oplus,fastchg-fod-parm-len, only for new projects
		 *                               old projects: WLS_FOD_PARM_LEN_MAX is 32
		 *                               new projects: WLS_FOD_PARM_LEN_MAX is 64
		 * oplus,fastchg-fod-parm-len: fod parm length, DO NOT include wls_base(dock) id
		 * oplus,fastchg-fod-parm: | wls_base(dock) id | WLS_FOD_PARM_LEN_MAX(32) pieces of fod parms |
		 *                         default wls_base id is 0xff
		 * oplus,disable-fod-parm: disable fod parm, DO NOT include wls_base(dock) id
		 */
		oplus,fastchg-fod-enable;
		oplus,fastchg-match-q = /bits/ 8 <0x00 0x41 0x55
						  0x01 0x41 0x55
						  0x02 0x68 0x55
						  0x03 0x64 0x55
						  0x04 0x10 0x5A
						  0x05 0x08 0x5A
						  0x1f 0x58 0x55>;
		oplus,fastchg-match-q-magcvr = /bits/ 8 <0x00 0x30 0x55
							 0x01 0x30 0x55
							 0x02 0x46 0x55
							 0x03 0x49 0x55
							 0x04 0x13 0x5A
							 0x05 0x0F 0x5A
							 0x1f 0x3C 0x55>;
		oplus,fod-parm-array-row-len = <33>;
		oplus,fastchg-fod-parm-len = <32>;
		/*oplus,fastchg-fod-parm = /bits/ 8 <0xff  0xff 0x7f 0xff 0x7f 0xa1 0x10 0x9e 0x7f 0xae 0x00 0xa8 0x7f 0xa7 0x40
							 0xff 0xff 0xff 0xff 0xff 0xff 0xff 0xff 0xff 0xff 0xff 0xff 0xff 0xff 0xff 0xff 0xff 0xff>;*/
		/*wls_base(dock) id | fod parms*/
		oplus,fastchg-fod-parm =	/bits/ 8 <0x01  0x91 0x3C 0x91 0x3C 0x91 0x32 0x91 0x32 0x91 0x32 0x91 0x32 0x94 0x41 0x99 0x4B
								0x9C 0x4B 0x9C 0x4B 0x9D 0x50 0x9E 0x50 0xAA 0x5F 0xAA 0x5F 0xA9 0x55 0xA9 0x55
							  0x02  0x96 0x3C 0x96 0x3C 0x96 0x32 0x96 0x32 0x96 0x32 0x96 0x32 0x96 0x32 0x98 0x34
								0x98 0x48 0x98 0x50 0x98 0x50 0x98 0x52 0xA5 0x5F 0xA0 0x55 0x9B 0x55 0x9B 0x55
							  0x03  0x8C 0x42 0x8C 0x42 0x96 0x3C 0x96 0x3C 0x96 0x3C 0x96 0x3C 0x96 0x3C 0x98 0x3C
								0x9A 0x50 0x9C 0x5A 0x9E 0x5A 0x9E 0x5A 0xA5 0x69 0xA7 0x6E 0xA7 0x6E 0xA7 0x6E
							  0x04  0x55 0x32 0x5A 0x32 0x5A 0x37 0x64 0x3C 0x6F 0x3C 0x7C 0x3F 0x80 0x41 0x84 0x4B
								0x86 0x50 0x88 0x5A 0x8A 0x5A 0x8C 0x5C 0x99 0x5F 0xA0 0x64 0xA0 0x64 0xA0 0x64
							  0x05  0x96 0x28 0x7B 0x28 0x7B 0x28 0x72 0x3C 0x81 0x3C 0x93 0x21 0x9E 0x35 0x9B 0x3A
								0x96 0x50 0x9A 0x7B 0xA6 0x56 0xA8 0x2D 0xB5 0x3C 0xB6 0x46 0xB6 0x32 0xB6 0x46
							  0x1f  0x96 0x46 0x96 0x46 0x96 0x3C 0x96 0x3C 0x96 0x3C 0x96 0x3C 0x96 0x3C 0x98 0x3E
								0x98 0x48 0x98 0x5A 0x98 0x5A 0x98 0x5C 0xA5 0x69 0xA0 0x5F 0x9B 0x5F 0x9B 0x5F
							  0xff  0x96 0x46 0x96 0x46 0x96 0x3C 0x96 0x3C 0x96 0x3C 0x96 0x3C 0x96 0x3C 0x98 0x3E
								0x98 0x48 0x98 0x5A 0x98 0x5A 0x98 0x5C 0xA5 0x69 0xA0 0x5F 0x9B 0x5F 0x9B 0x5F>;
		oplus,fastchg-fod-parm-magcvr = /bits/ 8 <0x01  0x91 0x3C 0x91 0x3C 0x91 0x32 0x91 0x32 0x91 0x32 0x91 0x32 0x94 0x41 0x99 0x4B
								0x9C 0x4B 0x9C 0x4B 0x9D 0x50 0x9E 0x50 0xAA 0x5F 0xAA 0x5F 0xA9 0x55 0xA9 0x55
							  0x02  0xA8 0x32 0xA8 0x32 0x9E 0x32 0x9B 0x32 0xA0 0x32 0xA0 0x32 0xA0 0x34 0xA0 0x34
								0xA0 0x4A 0xA0 0x4A 0xA2 0x4A 0xA2 0x4A 0xAF 0x64 0xAF 0x64 0xAA 0x69 0xA5 0x69
							  0x03  0xA8 0x46 0xA8 0x46 0x96 0x46 0x9B 0x41 0x9D 0x41 0x9B 0x41 0x9B 0x41 0x9C 0x41
								0x9D 0x5A 0x9E 0x5F 0xA0 0x5F 0xA0 0x5F 0xAA 0x70 0xAA 0x73 0xA7 0x73 0xA7 0x73
							  0x04  0x91 0x3C 0x91 0x3C 0x91 0x32 0x91 0x32 0x91 0x32 0x91 0x32 0x94 0x41 0x99 0x4B
								0x9C 0x4B 0x9C 0x4B 0x9D 0x50 0x9E 0x50 0xAA 0x5F 0xAA 0x5F 0xA9 0x55 0xA9 0x55
							  0x05  0xA0 0x3C 0xA3 0x46 0xA5 0x50 0xA5 0x46 0xA5 0x3C 0xA5 0x3C 0xA5 0x3C 0xA5 0x3C
								0xA5 0x3C 0xA5 0x3C 0xA5 0x3C 0xA5 0x3C 0xB2 0x46 0xB2 0x50 0xB2 0x50 0xB2 0x50
							  0x1f  0xA8 0x3C 0xA8 0x3C 0x9E 0x3C 0x9B 0x3C 0xA0 0x3C 0xA0 0x3C 0xA0 0x3E 0xA0 0x3E
								0xA0 0x54 0xA0 0x54 0xA2 0x54 0xA2 0x54 0xAF 0x6E 0xAF 0x6E 0xAA 0x73 0xA5 0x73
							  0xff  0xA8 0x3C 0xA8 0x3C 0x9E 0x3C 0x9B 0x3C 0xA0 0x3C 0xA0 0x3C 0xA0 0x3E 0xA0 0x3E
								0xA0 0x54 0xA0 0x54 0xA2 0x54 0xA2 0x54 0xAF 0x6E 0xAF 0x6E 0xAA 0x73 0xA5 0x73>;
		oplus,bpp-fod-parm = 		/bits/ 8 <0xff  0x7D 0x28 0x7D 0x29 0x7F 0x2F 0x7F 0x30 0x7F 0x33 0x80 0x34 0x81 0x37 0x81 0x37
								0xFF 0xFF 0xFF 0xFF 0xFF 0xFF 0xFF 0xFF 0xFF 0xFF 0xFF 0xFF 0xFF 0xFF 0xFF 0xFF>;
		oplus,bpp-fod-parm-magcvr =	/bits/ 8 <0xff  0x7D 0x46 0x7D 0x47 0x7F 0x4D 0x7F 0x4E 0x7F 0x51 0x80 0x52 0x81 0x55 0x81 0x55
								0xFF 0xFF 0xFF 0xFF 0xFF 0xFF 0xFF 0xFF 0xFF 0xFF 0xFF 0xFF 0xFF 0xFF 0xFF 0xFF>;
		oplus,epp-fod-parm =		/bits/ 8 <0xff  0x78 0x10 0x74 0x11 0x74 0x11 0x7A 0x14 0x7F 0x19 0x80 0x1A 0x81 0x1C 0x83 0x23
								0xFF 0xFF 0xFF 0xFF 0xFF 0xFF 0xFF 0xFF 0xFF 0xFF 0xFF 0xFF 0xFF 0xFF 0xFF 0xFF>;
		oplus,epp-fod-parm-magcvr =	/bits/ 8 <0xff  0x7B 0x26 0x7F 0x28 0x80 0x28 0x81 0x1F 0x82 0x1E 0x83 0x1E 0x84 0x22 0x85 0x26
								0xFF 0xFF 0xFF 0xFF 0xFF 0xFF 0xFF 0xFF 0xFF 0xFF 0xFF 0xFF 0xFF 0xFF 0xFF 0xFF>;
		/*only fod parms*/
		oplus,disable-fod-parm =	/bits/ 8 <0xff 0xff 0xff 0xff 0xff 0xff 0xff 0xff 0xff 0xff 0xff 0xff 0xff 0xff 0xff 0xff
							  0xff 0xff 0xff 0xff 0xff 0xff 0xff 0xff 0xff 0xff 0xff 0xff 0xff 0xff 0xff 0xff>;
		oplus,epp-high-temp-force-bpp-thr = <440>;
		oplus,bpp-vol-mv = <5500>;
		oplus,epp-vol-mv = <6000>;
		oplus,epp_plus-vol-mv = <6000>;
		oplus,vooc-vol-mv = <6400>;
		oplus,svooc-vol-mv = <10000>;
		oplus,fastchg-init-vout-mv = <6400>;
		oplus,full-bridge-vout-mv = <9200>;
		oplus,cp-open-offset-mv = <300>;
		oplus,cp-open-offset-min-mv = <100>;
		oplus,fastch-wait-thr-mv = <4180>;

		oplus,fastchg-max-vbat = <4400 4400 3880 3930 4400 4400 4400 4400 4400 4400>;
		oplus,fastchg-max-soc = <94>;
		oplus,fastchg-max-temp = <440>;
		oplus,strategy_soc = <20 35 55 75 85 95>;
		oplus,boot_quiet_time = <30>;

		/*
		 * | temp_min | temp_max | icl_curr | fcc_curr | need_wait |
		 */
		oplus,wls_epp_strategy =	<0 350 1500 2000 1
						 335 360 1100 1600 1
						 350 460 800 1000 1
						 440 530 400 1000 1>;
		oplus,wls_epp_plus_strategy =	<0 330 1700 2200 1
						 310 350 1500 2000 1
						 335 360 1100 1600 1
						 350 460 800 1000 1
						 440 530 400 1000 1>;
		oplus,wls_bpp_strategy =	<0 460 750 1000 1
						 440 530 400 1000 1>;

		/*
		 * | temp_min | temp_max | target_curr_ma | vol_max_mv | need_wait |
		 *
		 * temp_min: Switch to the previous level when the temperature is lower
		 *           than this value. If it is 0, do not switch.
		 * temp_max: Switch to the next level when the temperature is greater
		 *           than this value
		 * target_curr_ma: Target current in this temperature range.
		 * vol_max_mv: Maximum battery voltage.
		 * need_wait: 1:Need wait for a while after switching to the next level.
		 *            0:No need to wait after switching to the next level.
		 */
		non_ffc_strategy {
			wls_bpp_strategy {
				strategy_low_battery {
					wls_temp_little_cold = <(-100) 0 450 5000 0>;
					wls_temp_cool =	<0 50 750 5000 0>;
					wls_temp_little_cool = <50 120 750 5000 0>;
					wls_temp_pre_normal = <120 160 750 5000 0>;
					wls_temp_normal = <160 350 750 5000 0>;
					wls_temp_normal_high = <350 450 750 5000 0>;
					wls_temp_warm = <450 530 750 5000 0>;
				};
				strategy_high_battery {
					wls_temp_little_cold = <(-100) 0 250 5000 0>;
					wls_temp_cool =	<0 50 450 5000 0>;
					wls_temp_little_cool = <50 120 750 5000 0>;
					wls_temp_pre_normal = <120 160 750 5000 0>;
					wls_temp_normal = <160 350 750 5000 0>;
					wls_temp_normal_high = <350 450 750 5000 0>;
					wls_temp_warm = <450 530 750 5000 0>;
				};
			};

			wls_epp_strategy {
				strategy_low_battery {
					wls_temp_little_cold = <(-100) 0 400 5000 0>;
					wls_temp_cool =	<0 50 1500 4415 0
							0 50 1100 4435 0
							0 50 800 5000 0>;
					wls_temp_little_cool = <50 120 1500 4415 0
							50 120 1100 4435 0
							50 120 800 5000 0>;
					wls_temp_pre_normal = <120 160 1500 4415 0
							120 160 1100 4435 0
							120 160 800 5000 0>;
					wls_temp_normal = <160 350 1500 4415 0
							160 350 1100 4435 0
							160 350 800 5000 0>;
					wls_temp_normal_high = <350 450 1500 4400 0
							350 450 1100 4420 0
							350 450 800 5000 0>;
					wls_temp_warm = <450 530 800 5000 0>;
				};
				strategy_high_battery {
					wls_temp_little_cold = <(-100) 0 200 5000 0>;
					wls_temp_cool =	<0 50 400 5000 0>;
					wls_temp_little_cool = <50 120 950 4435 0
							50 120 800 5000 0>;
					wls_temp_pre_normal = <120 160 1500 4415 0
							120 160 1100 4435 0
							120 160 800 5000 0>;
					wls_temp_normal = <160 350 1500 4415 0
							160 350 1100 4435 0
							160 350 800 5000 0>;
					wls_temp_normal_high = <350 450 1500 4400 0
							350 450 1100 4420 0
							350 450 800 5000 0>;
					wls_temp_warm = <450 530 800 5000 0>;
				};
			};

			wls_epp_plus_strategy {
				strategy_low_battery {
					wls_temp_little_cold = <(-100) 0 400 5000 0>;
					wls_temp_cool =	<0 50 1500 4415 0
							0 50 1100 4435 0
							0 50 800 5000 0>;
					wls_temp_little_cool = <50 120 1700 4410 0
							50 120 1500 4415 0
							50 120 1100 4435 0
							50 120 800 5000 0>;
					wls_temp_pre_normal = <120 160 1700 4410 0
							120 160 1500 4415 0
							120 160 1100 4435 0
							120 160 800 5000 0>;
					wls_temp_normal = <160 350 1700 4410 0
							160 350 1500 4415 0
							160 350 1100 4435 0
							160 350 800 5000 0>;
					wls_temp_normal_high = <350 450 1700 4395 0
							350 450 1500 4400 0
							350 450 1100 4420 0
							350 450 800 5000 0>;
					wls_temp_warm = <450 530 800 5000 0>;
				};
				strategy_high_battery {
					wls_temp_little_cold = <(-100) 0 200 5000 0>;
					wls_temp_cool =	<0 50 400 5000 0>;
					wls_temp_little_cool = <50 120 950 4435 0
							50 120 800 5000 0>;
					wls_temp_pre_normal = <120 160 1500 4415 0
							120 160 1100 4435 0
							120 160 800 5000 0>;
					wls_temp_normal = <160 350 1700 4410 0
							160 350 1500 4415 0
							160 350 1100 4435 0
							160 350 800 5000 0>;
					wls_temp_normal_high = <350 450 1700 4395 0
							350 450 1500 4400 0
							350 450 1100 4420 0
							350 450 800 5000 0>;
					wls_temp_warm = <450 530 800 5000 0>;
				};
			};

			wls_airvooc_strategy {
				strategy_low_battery {
					wls_temp_little_cold = <(-100) 0 400 5000 0>;
					wls_temp_cool =	<0 50 1450 4415 0
							0 50 750 5000 0>;
					wls_temp_little_cool = <50 120 1800 4405 0
							50 120 750 5000 0>;
					wls_temp_pre_normal = <120 160 1800 4405 0
							120 160 750 5000 0>;
					wls_temp_normal = <160 350 1800 4405 0
							160 350 750 5000 0>;
					wls_temp_normal_high = 	<350 450 1800 4390 0
							350 450 750 5000 0>;
					wls_temp_warm = <450 530 750 5000 0>;
				};
				strategy_high_battery {
					wls_temp_little_cold = <(-100) 0 200 5000 0>;
					wls_temp_cool =	<0 50 400 5000 0>;
					wls_temp_little_cool = <50 120 900 4435 0
							50 120 750 5000 0>;
					wls_temp_pre_normal = <120 160 1450 4415 0
							120 160 750 5000 0>;
					wls_temp_normal = <160 350 1800 4405 0
							160 350 750 5000 0>;
					wls_temp_normal_high = 	<350 450 1800 4390 0
							350 450 750 5000 0>;
					wls_temp_warm = <450 530 750 5000 0>;
				};
			};

			wls_airsvooc_strategy {
				strategy_low_battery {
					wls_temp_little_cold = <(-100) 0 400 5000 0>;
					wls_temp_cool =	<0 50 1450 4415 0
							0 50 750 5000 0>;
					wls_temp_little_cool = <50 120 1800 4405 0
							50 120 750 5000 0>;
					wls_temp_pre_normal = <120 160 1800 4405 0
							120 160 750 5000 0>;
					wls_temp_normal = <160 350 1800 4405 0
							160 350 750 5000 0>;
					wls_temp_normal_high = 	<350 450 1100 4420 0
							350 450 750 5000 0>;
					wls_temp_warm = <450 530 750 5000 0>;
				};
				strategy_high_battery {
					wls_temp_little_cold = <(-100) 0 200 5000 0>;
					wls_temp_cool =	<0 50 400 5000 0>;
					wls_temp_little_cool = <50 120 900 4435 0
							50 120 750 5000 0>;
					wls_temp_pre_normal = <120 160 1450 4415 0
							120 160 750 5000 0>;
					wls_temp_normal = <160 350 1800 4405 0
							160 350 750 5000 0>;
					wls_temp_normal_high = 	<350 450 1100 4420 0
							350 450 750 5000 0>;
					wls_temp_warm = <450 530 750 5000 0>;
				};
			};
		};

		/*
		 * | temp_min | temp_max | target_curr_ma | vol_max_mv | need_wait |
		 *
		 * temp_min: Switch to the previous level when the temperature is lower
		 *           than this value. If it is 0, do not switch.
		 * temp_max: Switch to the next level when the temperature is greater
		 *           than this value
		 * target_curr_ma: Target current in this temperature range.
		 * vol_max_mv: Maximum battery voltage.
		 * need_wait: 1:Need wait for a while after switching to the next level.
		 *            0:No need to wait after switching to the next level.
		 *            >1:Max running time(seconds) of this level
		 */
		wireless_fastchg_strategy {
			/* 0~20 */
			strategy_soc_0_to_30 {
				strategy_temp_0_to_50 =		<0 440 1000 4050 0>;		//0~5
				strategy_temp_50_to_120 =	<50 430 1600 4040 1		//5~12
								 50 430 1500 4040 1
								 50 440 1000 4050 0>;
				strategy_temp_120_to_160 = 	<120 330 2700 4050 1		//12~16
								 315 340 2500 4050 1
								 330 360 2000 4050 1
								 360 380 1600 4190 1
								 360 380 1500 4190 1
								 395 440 1000 4200 0>;
				strategy_temp_160_to_400 =      <120 310 3500 4050 1		//16~21
								 290 320 3000 4050 1
								 300 330 2700 4150 1
								 315 340 2500 4150 1
								 330 360 2000 4150 1
								 360 380 1500 4150 1
								 395 440 1000 4550 0>;
				/* 21 ~ little warm */
				strategy_temp_160_to_400_high = <120 300 5000 4380 30		//21~35
								 160 310 3500 4540 1
								 290 320 3000 4540 1
								 315 340 2500 4540 1
								 330 360 2000 4540 1
								 350 370 1750 4540 1
								 360 380 1500 4540 1
								 375 400 1250 4540 1
								 395 440 1000 4550 0>;
				strategy_temp_400_to_440 =      <120 300 5000 4380 30		//35~44
								 160 310 3500 4540 1
								 290 320 3000 4540 1
								 315 340 2500 4540 1
								 330 360 2000 4540 1
								 360 380 1500 4540 1
								 395 440 1000 4545 0>;
			};

			/* 21~35 */
			strategy_soc_0_to_30_high {
				strategy_temp_0_to_50 =		<0 440 1000 4050 0>;		//0~5
				strategy_temp_50_to_120 =	<50 430 1600 4040 1		//5~12
								 50 430 1500 4040 1
								 50 440 1000 4050 0>;
				strategy_temp_120_to_160 = 	<120 330 2700 4050 1		//12~16
								 315 340 2500 4050 1
								 330 360 2000 4050 1
								 360 380 1600 4190 1
								 360 380 1500 4190 1
								 395 440 1000 4200 0>;
				strategy_temp_160_to_400 =      <120 310 3500 4050 1		//16~21
								 290 320 3000 4050 1
								 300 330 2700 4150 1
								 315 340 2500 4150 1
								 330 360 2000 4150 1
								 360 380 1500 4150 1
								 395 440 1000 4550 0>;
				/* 21 ~ little warm */
				strategy_temp_160_to_400_high = <120 310 3500 4540 1		//21~35
								 290 320 3000 4540 1
								 315 340 2500 4540 1
								 330 360 2000 4540 1
								 350 370 1750 4540 1
								 360 380 1500 4540 1
								 375 400 1250 4540 1
								 395 440 1000 4550 0>;
				strategy_temp_400_to_440 =      <120 310 3500 4540 1		//35~44
								 290 320 3000 4540 1
								 315 340 2500 4540 1
								 330 360 2000 4540 1
								 360 380 1500 4540 1
								 395 440 1000 4545 0>;
			};

			/* 36~55 */
			strategy_soc_30_to_70 {
				strategy_temp_0_to_50 =		<0 440 1000 4050 0>;		//0~5
				strategy_temp_50_to_120 =	<50 430 1600 4040 1             //5~12
								 50 430 1500 4040 1
								 50 440 1000 4050 0>;
				strategy_temp_120_to_160 = 	<120 330 2700 4050 1		//12~16
								 315 340 2500 4050 1
								 330 360 2000 4050 1
								 360 380 1600 4190 1
								 360 380 1500 4190 1
								 395 440 1000 4200 0>;
				strategy_temp_160_to_400 =      <120 310 3500 4050 1		//16~21
								 290 320 3000 4050 1
								 300 330 2700 4150 1
								 315 340 2500 4150 1
								 330 360 2000 4150 1
								 360 380 1500 4150 1
								 395 440 1000 4550 0>;
				/* 21 ~ little warm */
				strategy_temp_160_to_400_high = <120 310 3500 4540 1		//21~35
								 290 320 3000 4540 1
								 315 340 2500 4540 1
								 330 360 2000 4540 1
								 350 370 1750 4540 1
								 360 380 1500 4540 1
								 375 400 1250 4540 1
								 395 440 1000 4550 0>;
				strategy_temp_400_to_440 =      <120 310 3500 4540 1		//35~44
								 290 320 3000 4540 1
								 315 340 2500 4540 1
								 330 360 2000 4540 1
								 360 380 1500 4540 1
								 395 440 1000 4545 0>;
			};

			/* 56~75 */
			strategy_soc_30_to_70_high {
				strategy_temp_0_to_50 =		<0 440 1000 4050 0>;		//0~5
				strategy_temp_50_to_120 =	<50 430 1500 4040 1             //5~12
								 50 440 1000 4050 0>;
				strategy_temp_120_to_160 = 	<120 360 2000 4050 1		//12~16
								 360 380 1600 4190 1
								 360 380 1500 4190 1
								 395 440 1000 4200 0>;
				strategy_temp_160_to_400 =      <120 360 2000 4150 1		//16~21
								 360 380 1500 4150 1
								 395 440 1000 4550 0>;
				/* 21 ~ little warm */
				strategy_temp_160_to_400_high = <120 340 2500 4540 1		//21~35
								 330 360 2000 4540 1
								 350 370 1750 4540 1
								 360 380 1500 4540 1
								 375 400 1250 4540 1
								 395 440 1000 4550 0>;
				strategy_temp_400_to_440 =      <120 320 3000 4540 1		//35~44
								 315 340 2500 4540 1
								 330 360 2000 4540 1
								 360 380 1500 4540 1
								 395 440 1000 4545 0>;
			};

			/* 76~85 */
			strategy_soc_70_to_90 {
				strategy_temp_0_to_50 =		<0 440 1000 4050 0>;		//0~5
				strategy_temp_50_to_120 =	<0 440 1000 4050 0>;		//5~12
				strategy_temp_120_to_160 = 	<120 380 1500 4190 1		//12~16
								 395 440 1000 4200 0>;
				strategy_temp_160_to_400 =      <120 380 1500 4150 1		//16~21
								 395 440 1000 4550 0>;
				/* 21 ~ little warm */
				strategy_temp_160_to_400_high = <120 380 1500 4540 1		//21~35
								 375 400 1250 4540 1
								 395 440 1000 4550 0>;
				strategy_temp_400_to_440 =      <120 360 2000 4540 1		//35~44
								 360 380 1500 4540 1
								 395 440 1000 4545 0>;
			};

			/* 85~95 */
			strategy_soc_70_to_90_high {
				strategy_temp_0_to_50 =		<0 440 1000 4050 0>;		//0~5
				strategy_temp_50_to_120 =	<0 440 1000 4050 0>;		//5~12
				strategy_temp_120_to_160 =	<0 440 1000 4200 0>;		//12~16
				strategy_temp_160_to_400 =	<0 440 1000 4550 0>;		//16~21
				strategy_temp_160_to_400_high =	<0 440 1000 4550 0>;		//21~35
				strategy_temp_400_to_440 =	<0 440 1000 4545 0>;		//35~44
			};
		};

		wireless_fastchg_strategy_magcvr {
			/* 0~20 */
			strategy_soc_0_to_30 {
				strategy_temp_0_to_50 =		<0 440 1000 4050 0>;		//0~5
				strategy_temp_50_to_120 =	<50 430 1600 4040 1		//5~12
								 50 430 1500 4040 1
								 50 440 1000 4050 0>;
				strategy_temp_120_to_160 = 	<120 365 2700 4050 1		//12~16
								 345 405 2500 4050 1
								 385 425 2000 4050 1
								 400 430 1600 4190 1
								 400 430 1500 4190 1
								 410 440 1000 4200 0>;
				strategy_temp_160_to_400 =      <120 343 3500 4050 1		//16~21
								 323 365 3000 4050 1
								 345 385 2700 4150 1
								 345 405 2500 4150 1
								 385 425 2000 4150 1
								 400 430 1500 4150 1
								 410 440 1000 4550 0>;
				/* 21 ~ little warm */
				strategy_temp_160_to_400_high = <120 310 5000 4380 30		//21~35
								 160 343 3500 4540 1
								 323 365 3000 4540 1
								 345 385 2550 4540 1
								 365 405 2500 4540 1
								 385 425 2000 4540 1
								 400 430 1500 4540 1
								 410 440 1000 4550 0>;
				strategy_temp_400_to_440 =      <120 310 5000 4380 30		//35~44
								 160 343 3500 4540 1
								 323 365 3000 4540 1
								 345 405 2500 4540 1
								 385 425 2000 4540 1
								 400 430 1500 4540 1
								 410 440 1000 4545 0>;
			};

			/* 21~35 */
			strategy_soc_0_to_30_high {
				strategy_temp_0_to_50 =		<0 440 1000 4050 0>;		//0~5
				strategy_temp_50_to_120 =	<50 430 1600 4040 1		//5~12
								 50 430 1500 4040 1
								 50 440 1000 4050 0>;
				strategy_temp_120_to_160 = 	<120 365 2700 4050 1		//12~16
								 345 405 2500 4050 1
								 385 425 2000 4050 1
								 400 430 1600 4190 1
								 400 430 1500 4190 1
								 410 440 1000 4200 0>;
				strategy_temp_160_to_400 =      <120 343 3500 4050 1		//16~21
								 323 365 3000 4050 1
								 345 385 2700 4150 1
								 345 405 2500 4150 1
								 385 425 2000 4150 1
								 400 430 1500 4150 1
								 410 440 1000 4550 0>;
				/* 21 ~ little warm */
				strategy_temp_160_to_400_high = <120 343 3500 4540 1		//21~35
								 323 365 3000 4540 1
								 345 405 2500 4540 1
								 385 425 2000 4540 1
								 400 430 1500 4540 1
								 410 440 1000 4550 0>;
				strategy_temp_400_to_440 =      <120 343 3500 4540 1		//35~44
								 323 365 3000 4540 1
								 345 405 2500 4540 1
								 385 425 2000 4540 1
								 400 430 1500 4540 1
								 410 440 1000 4545 0>;
			};

			/* 36~55 */
			strategy_soc_30_to_70 {
				strategy_temp_0_to_50 =		<0 440 1000 4050 0>;		//0~5
				strategy_temp_50_to_120 =	<50 430 1600 4040 1		//5~12
								 50 430 1500 4040 1
								 50 440 1000 4050 0>;
				strategy_temp_120_to_160 = 	<120 365 2700 4050 1		//12~16
								 345 405 2500 4050 1
								 385 425 2000 4050 1
								 400 430 1600 4190 1
								 400 430 1500 4190 1
								 410 440 1000 4200 0>;
				strategy_temp_160_to_400 =      <120 343 3500 4050 1		//16~21
								 323 365 3000 4050 1
								 345 385 2700 4150 1
								 345 405 2500 4150 1
								 385 425 2000 4150 1
								 400 430 1500 4150 1
								 410 440 1000 4550 0>;
				/* 21 ~ little warm */
				strategy_temp_160_to_400_high = <120 343 3500 4540 1		//21~35
								 323 365 3000 4540 1
								 345 405 2500 4540 1
								 385 425 2000 4540 1
								 400 430 1500 4540 1
								 410 440 1000 4550 0>;
				strategy_temp_400_to_440 =      <120 343 3500 4540 1		//35~44
								 323 365 3000 4540 1
								 345 405 2500 4540 1
								 385 425 2000 4540 1
								 400 430 1500 4540 1
								 410 440 1000 4545 0>;
			};

			/* 56~75 */
			strategy_soc_30_to_70_high {
				strategy_temp_0_to_50 =		<0 440 1000 4050 0>;		//0~5
				strategy_temp_50_to_120 =	<50 430 1500 4040 1		//5~12
								 50 440 1000 4050 0>;
				strategy_temp_120_to_160 = 	<120 425 2000 4050 1		//12~16
								 400 430 1600 4190 1
								 400 430 1500 4190 1
								 410 440 1000 4200 0>;
				strategy_temp_160_to_400 =      <120 425 2000 4150 1		//16~21
								 400 430 1500 4150 1
								 410 440 1000 4550 0>;
				/* 21 ~ little warm */
				strategy_temp_160_to_400_high = <120 405 2500 4540 1		//21~35
								 385 425 2000 4540 1
								 400 430 1500 4540 1
								 410 440 1000 4550 0>;
				strategy_temp_400_to_440 =      <120 365 3000 4540 1		//35~44
								 345 405 2500 4540 1
								 385 425 2000 4540 1
								 400 430 1500 4540 1
								 410 440 1000 4545 0>;
			};

			/* 76~85 */
			strategy_soc_70_to_90 {
				strategy_temp_0_to_50 =		<0 440 1000 4050 0>;		//0~5
				strategy_temp_50_to_120 =	<0 440 1000 4050 0>;		//5~12
				strategy_temp_120_to_160 = 	<120 430 1500 4190 1		//12~16
								 410 440 1000 4200 0>;
				strategy_temp_160_to_400 =      <120 430 1500 4150 1		//16~21
								 410 440 1000 4550 0>;
				/* 21 ~ little warm */
				strategy_temp_160_to_400_high = <120 430 1500 4540 1		//21~35
								 410 440 1000 4550 0>;
				strategy_temp_400_to_440 =      <120 425 2000 4540 1		//35~44
								 400 430 1500 4540 1
								 410 440 1000 4545 0>;
			};

			/* 85~95 */
			strategy_soc_70_to_90_high {
				strategy_temp_0_to_50 =		<0 440 1000 4050 0>;		//0~5
				strategy_temp_50_to_120 =	<0 440 1000 4050 0>;		//5~12
				strategy_temp_120_to_160 =	<0 440 1000 4200 0>;		//12~16
				strategy_temp_160_to_400 =	<0 440 1000 4550 0>;		//16~21
				strategy_temp_160_to_400_high =	<0 440 1000 4550 0>;		//21~35
				strategy_temp_400_to_440 =	<0 440 1000 4545 0>;		//35~44
			};
		};

		/*
		 * | max_batt_volt | max_current | min_current | end
		 *
		 * max_batt_volt: Maximum battery voltage.
		 * max_current: The maximum current in this interval.
		 * min_current: The result obtained by subtracting 1A from the
		 *				minimum current in this interval. Minimum not less than 1A.
		 * exit: Whether the curve ends or not.
		 */
		wireless_bcc_table {
			/* 0~20 */
			bcc_soc_0_to_30 {
				bcc_temp_0_to_50 =	<4050 2000 2000 1>;			//0~5
				bcc_temp_50_to_120 =	<4040 3200 2000 0			//5~12
							 4050 2000 2000 1>;
				bcc_temp_120_to_160 =	<4050 5400 4000 0			//12~16
							 4190 3200 2000 0
							 4200 2000 2000 1>;
				bcc_temp_160_to_400 =	<4050 7000 6000 0			//16~21
							 4150 5400 4000 0
							 4550 2000 2000 1>;
				bcc_temp_160_to_400_high =	<4380 10000 9000 0		//21~35
							 4540 7000 6000 0
							 4550 2000 2000 1>;
				bcc_temp_400_to_440 =	<4380 10000 9000 0			//35~44
							 4540 7000 6000 0
							 4545 2000 2000 1>;
			};

			/* 21~35 */
			bcc_soc_0_to_30_high {
				bcc_temp_0_to_50 =	<4050 2000 2000 1>;			//0~5
				bcc_temp_50_to_120 =	<4040 3200 2000 0			//5~12
							 4050 2000 2000 1>;
				bcc_temp_120_to_160 =	<4050 5400 4000 0			//12~16
							 4190 3200 2000 0
							 4200 2000 2000 1>;
				bcc_temp_160_to_400 =	<4050 7000 6000 0			//16~21
							 4150 5400 4000 0
							 4550 2000 2000 1>;
				bcc_temp_160_to_400_high =	<4540 7000 6000 0		//21~35
							 4550 2000 2000 1>;
				bcc_temp_400_to_440 =	<4540 7000 6000 0			//35~44
							 4545 2000 2000 1>;
			};

			/* 36~55 */
			bcc_soc_30_to_70 {
				bcc_temp_0_to_50 =	<4050 2000 2000 1>;			//0~5
				bcc_temp_50_to_120 =	<4040 3200 2000 0			//5~12
							 4050 2000 2000 1>;
				bcc_temp_120_to_160 =	<4050 5400 4000 0			//12~16
							 4190 3200 2000 0
							 4200 2000 2000 1>;
				bcc_temp_160_to_400 =	<4050 7000 6000 0			//16~21
							 4150 5400 4000 0
							 4550 2000 2000 1>;
				bcc_temp_160_to_400_high =	<4540 7000 6000 0		//21~35
							 4550 2000 2000 1>;
				bcc_temp_400_to_440 =	<4540 7000 6000 0			//35~44
							 4545 2000 2000 1>;
			};

			/* 56~75 */
			bcc_soc_30_to_70_high {
				bcc_temp_0_to_50 =	<4050 2000 2000 1>;			//0~5
				bcc_temp_50_to_120 =	<4040 3000 2000 0			//5~12
							 4050 2000 2000 1>;
				bcc_temp_120_to_160 =	<4050 4000 3000 0			//12~16
							 4190 3200 2000 0
							 4200 2000 2000 1>;
				bcc_temp_160_to_400 =	<4150 4000 3000 0			//16~21
							 4550 2000 2000 1>;
				bcc_temp_160_to_400_high =	<4540 5000 4000 0		//21~35
							 4550 2000 2000 1>;
				bcc_temp_400_to_440 =	<4540 6000 5000 0			//35~44
							 4545 2000 2000 1>;
			};

			/* 76~85 */
			bcc_soc_70_to_90 {
				bcc_temp_0_to_50 =	<4050 2000 2000 1>;			//0~5
				bcc_temp_50_to_120 =	<4050 2000 2000 1>;			//5~12
				bcc_temp_120_to_160 =	<4190 3000 2000 0			//12~16
							 4200 2000 2000 1>;
				bcc_temp_160_to_400 =	<4150 3000 2000 0			//16~21
							 4550 2000 2000 1>;
				bcc_temp_160_to_400_high =	<4540 3000 2000 0		//21~35
							 4550 2000 2000 1>;
				bcc_temp_400_to_440 =	<4540 4000 3000 0			//35~44
							 4545 2000 2000 1>;
			};

			/* 85~95 */
			bcc_soc_70_to_90_high {
				bcc_temp_0_to_50 =	<4050 2000 2000 1>;			//0~5
				bcc_temp_50_to_120 =	<4050 2000 2000 1>;			//5~12
				bcc_temp_120_to_160 =	<4200 2000 2000 1>;			//12~16
				bcc_temp_160_to_400 =	<4550 2000 2000 1>;			//16~21
				bcc_temp_160_to_400_high =	<4550 2000 2000 1>;		//21~35
				bcc_temp_400_to_440 =	<4545 2000 2000 1>;			//35~44
			};
		};
	};
};

&soc {
	oplus_virtual_rx: oplus,virtual_rx {
		compatible = "oplus,virtual_rx";
		oplus,rx_ic = <&oplus_rx_sc96257>;
		oplus,rx_ic_index = <0>;
		oplus,rx_ic_func_group = <&sc96257_rx_groups>;
		oplus,ic_type = <OPLUS_CHG_IC_VIRTUAL_RX>;
		oplus,ic_index = <0>;
	};
	oplus_wls_virtual_cp: oplus,wls_virtual_cp {
		compatible = "oplus,virtual_cp";

		oplus,ic_type = <OPLUS_CHG_IC_VIRTUAL_CP>;
		oplus,ic_index = <1>;

		oplus,cp_ic = <&oplus_sc8547_cp &oplus_sc8547_slave_cp>;
		oplus,input_curr_max_ma = <3000 3000>;

		oplus,cp_ic_connect = <OPLUS_CHG_IC_CONNECT_PARALLEL>;
		oplus,main_cp = <0>;

		oplus,cp_strategy = <CP_STRAT_OPEN_ALL>;
	};
};

&tlmm {
	rx_event_default: rx_event_default {
		mux {
			pins = "gpio169";
			function = "gpio";
		};
		config {
			pins = "gpio169";
			drive-strength = <2>;
			input-enable;
			bias-disable;
		};
	};

	rx_con_default: rx_con_default {
		mux {
			pins = "gpio57";
			function = "gpio";
		};
		config {
			pins = "gpio57";
			drive-strength = <2>;
			bias-disable;
			input-enable;
		};
	};
};

&pmih010x_gpios {
	rx_en_sleep: rx_en_sleep {
		pins = "gpio2";
		function = "normal";
		input-disable;
		bias-disable;
		power-source = <2>;
		output-high;
		qcom,drive-strength = <3>;
	};

	rx_en_active: rx_en_active {
		pins = "gpio2";
		function = "normal";
		input-disable;
		bias-disable;
		power-source = <2>;
		output-low;
		qcom,drive-strength = <3>;
	};

	insert_dis_active: insert_dis_active {
		pins = "gpio8";
		function = "normal";
		input-disable;
		bias-disable;
		power-source = <2>;
		output-high;
		qcom,drive-strength = <3>;
	};
	insert_dis_sleep: insert_dis_sleep {
		pins = "gpio8";
		function = "normal";
		input-disable;
		bias-disable;
		power-source = <2>;
		output-low;
		qcom,drive-strength = <3>;
	};
};

&qupv3_hub_i2c1_sda_active {
	config {
		qcom,i2c_pull;
	};
};
&qupv3_hub_i2c1_scl_active {
	config {
		qcom,i2c_pull;
	};
};

&qupv3_hub_i2c1 {
	status = "ok";
	qcom,clk-freq-out = <400000>;

	oplus_sc96257: oplus,sc96257@37 {
		status = "ok";
		compatible = "oplus,rx-sc96257";
		reg = <0x37>;
		#address-cells = <1>;
		#size-cells = <0>;
		oplus,nor_ic = <&oplus_virtual_buck>;
		oplus,support_epp_11w;

		oplus,rx_event-gpio = <&tlmm 169 0x00>;//check
		oplus,rx_con-gpio = <&tlmm 57 0x00>;//check
		oplus,rx_en-gpio = <&pmih010x_gpios 2 0x00>;//vt-sleep check
		oplus,insert_dis-gpio = <&pmih010x_gpios 8 0x00>;//wls force pd check
		pinctrl-names = "rx_event_default", "rx_con_default",
				"rx_en_sleep", "rx_en_active",
				"insert_dis_active", "insert_dis_sleep";
		pinctrl-0 = <&rx_event_default>;
		pinctrl-1 = <&rx_con_default>;
		pinctrl-2 = <&rx_en_sleep>;
		pinctrl-3 = <&rx_en_active>;
		pinctrl-4 = <&insert_dis_active>;
		pinctrl-5 = <&insert_dis_sleep>;

		oplus_rx_sc96257: oplus,rx_sc96257 {
			oplus,ic_type = <OPLUS_CHG_IC_RX>;
			oplus,ic_index = <0>;
		};
	};
};
//#endif OPLUS_FEATURE_CHG_BASIC /*for wls charging config*/
